VERSION "HIPBNNNYNNNNNNNNNNNNNNNNNNNNNNNNNNNNNNNNNN/4/%%%/4/'%**4NNN///"

NS_ :

BS_:

BU_: Vector__XXX xx TXU TSG SSG SMG RIP LWS Last INSTR GIB EKP EKAT EHC EGS EDCK DSC DME DIP DDE CRT CNG BFC BeCM ASP ASG ASC AIR_SUS ACC

BO_ 1584 RIP1: 8 RIP

BO_ 1583 TSG1: 8 TSG
 SG_ Vorzeichen : 7|1@1+ (1,0) [0|0] ""  DME
 SG_ T_UMG : 0|7@1+ (1,0) [0|0] "°C"  DME

BO_ 1567 INSTR6: 8 INSTR

BO_ 1562 INSTR5: 8 INSTR
 SG_ V_ODO_U m0 : 62|2@1+ (1,0) [0|0] ""  RIP
 SG_ V_COMP_U m1 : 61|1@1+ (1,0) [0|0] ""  RIP
 SG_ V_TEMP_U m1 : 60|1@1+ (1,0) [0|0] ""  RIP
 SG_ V_COMP_M m1 : 56|4@1+ (1,0) [0|0] ""  RIP
 SG_ V_TRIP1 m0 : 48|14@1+ (0.1,0) [0|6553.3] ""  RIP
 SG_ V_SIA m0 : 46|2@1+ (1,0) [0|0] ""  RIP
 SG_ V_ODO m0 : 24|20@1+ (1,0) [0|999999] ""  RIP
 SG_ V_COMP m1 : 24|16@1+ (1,0) [0|0] ""  RIP
 SG_ V_ID M : 22|2@1+ (1,0) [0|0] ""  RIP
 SG_ V_LED : 20|2@1+ (1,0) [0|0] ""  RIP
 SG_ V_WL : 8|12@1+ (1,0) [0|0] ""  RIP
 SG_ V_GPOS : 4|4@1+ (1,0) [0|0] ""  RIP
 SG_ V_GEAR : 0|4@1+ (1,0) [0|0] ""  RIP

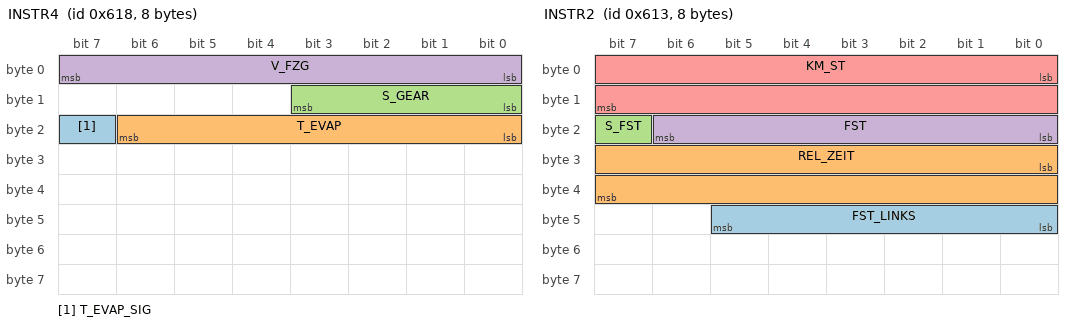
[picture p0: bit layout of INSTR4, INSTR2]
BO_ 1560 INSTR4: 8 INSTR
 SG_ T_EVAP_SIG : 23|1@1+ (1,0) [0|1] ""  DME,DDE
 SG_ T_EVAP : 16|7@1+ (1,0) [0|127] ""  DME,DDE
 SG_ S_GEAR : 8|4@1+ (1,0) [0|15] ""  ASC
 SG_ V_FZG : 0|8@1+ (1,0) [0|255] "km/h"  EGS,DME

BO_ 1557 INSTR3: 8 INSTR
 SG_ KEY_INFO : 56|3@1+ (1,0) [0|0] ""  DME
 SG_ V_ANZ : 46|10@1+ (0.5,0) [0|511] "km/h"  ACC
 SG_ F_K_OBD : 45|1@1+ (1,0) [0|1] ""  DME
 SG_ A_EKP_CRASH : 43|2@1+ (1,0) [0|3] ""  DDE,DME
 SG_ BLINKER : 41|2@1+ (1,0) [0|3] ""  ACC,DME
 SG_ F_K_ACC : 40|1@1+ (1,0) [0|1] ""  ACC,DME
 SG_ S_REGIME : 37|3@1+ (1,0) [0|7] ""  AIR_SUS,DME,EGS
 SG_ S_SUSP : 34|2@1+ (1,0) [0|3] ""  ASP,DME
 SG_ S_HBR : 33|1@1+ (1,0) [0|1] ""  ACC,ASC,ASP,DME,DSC
 SG_ S_DOOR : 32|1@1+ (1,0) [0|1] ""  ASP,DME
 SG_ T_UMG_SIGN : 31|1@1+ (1,0) [0|1] ""  DDE,DME
 SG_ T_UMG : 24|7@1+ (1,0) [0|127] "°C"  DME
 SG_ LB_NLL : 22|1@1+ (1,0) [0|0] ""  DDE,DME
 SG_ LB_USOLL : 16|6@1+ (0.1,0) [10.6|16.9] "V"  DDE,DME
 SG_ N_EL : 12|4@1+ (1,0) [0|15] ""  DDE,DME
 SG_ S_MH : 11|1@1+ (1,0) [0|0] ""  DME
 SG_ S_TNS : 10|1@1+ (1,0) [0|1] ""  DME,EDCK
 SG_ S_ANH : 9|1@1+ (1,0) [0|1] ""  DDE,DME
 SG_ S_HZL : 8|1@1+ (1,0) [0|1] ""  DDE,DME
 SG_ S_AC : 7|1@1+ (1,0) [0|1] ""  DDE,DME
 SG_ S_KO : 6|1@1+ (1,0) [0|1] ""  DDE,DME
 SG_ S_NTKW : 5|1@1+ (1,0) [0|1] ""  DME
 SG_ LM_KK : 0|5@1+ (1,0) [0|31] "Nm"  DDE,DME

BO_ 1555 INSTR2: 8 INSTR
 SG_ FST_LINKS : 40|6@1+ (1,0) [0|62] "Ltr."  DME
 SG_ REL_ZEIT : 24|16@1+ (1,0) [0|65535] "Min"  DSC,DME,ACC
 SG_ S_FST : 23|1@1+ (1,0) [0|0] ""  DME
 SG_ FST : 16|7@1+ (1,0) [0|126] "Ltr."  DME
 SG_ KM_ST : 0|16@1+ (10,0) [0|655340] "km"  EGS,DME

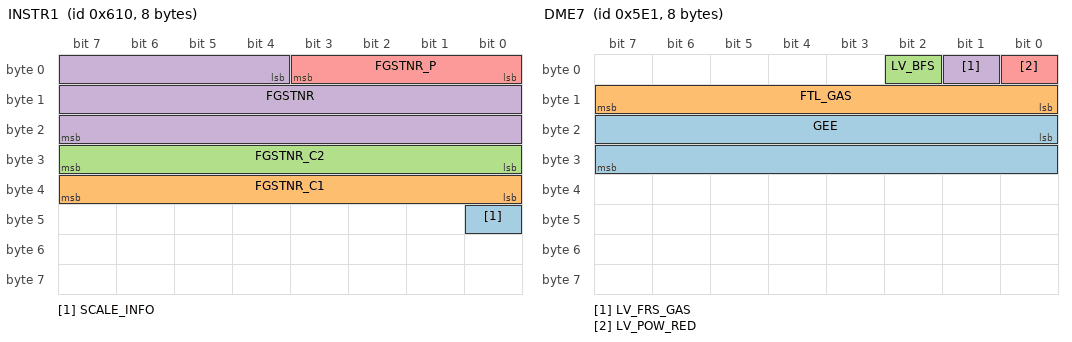
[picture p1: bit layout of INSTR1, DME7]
BO_ 1552 INSTR1: 8 INSTR
 SG_ SCALE_INFO : 40|1@1+ (1,0) [0|1] "" Vector__XXX
 SG_ FGSTNR_C1 : 32|8@1+ (1,0) [0|255] ""  LWS
 SG_ FGSTNR_C2 : 24|8@1+ (1,0) [0|255] ""  LWS
 SG_ FGSTNR : 4|20@1+ (1,0) [0|629145] ""  LWS
 SG_ FGSTNR_P : 0|4@1+ (1,0) [0|15] ""  LWS

BO_ 1505 DME7: 8 DME
 SG_ GEE : 16|16@1+ (0.003,0) [0|200] ""  INSTR
 SG_ FTL_GAS : 8|8@1+ (0.392,0) [0|99.96] "%"  INSTR
 SG_ LV_BFS : 2|1@1+ (1,0) [0|1] ""  INSTR
 SG_ LV_FRS_GAS : 1|1@1+ (1,0) [0|1] ""  INSTR
 SG_ LV_POW_RED : 0|1@1+ (1,0) [0|1] ""  INSTR

BO_ 1503 EDCK1: 8 EDCK
 SG_ EDCK_STA2 : 32|32@1+ (1,0) [0|4294970000] ""  xx
 SG_ EDCK_STA1 : 0|32@1+ (1,0) [0|4294970000] ""  xx

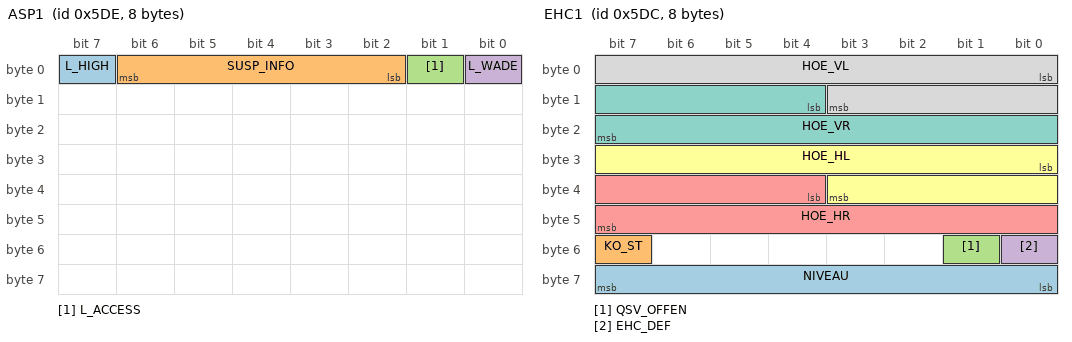
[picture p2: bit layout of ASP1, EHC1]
BO_ 1502 ASP1: 8 ASP
 SG_ L_HIGH : 7|1@1+ (1,0) [0|1] ""  BeCM
 SG_ SUSP_INFO : 2|5@1+ (1,0) [0|31] ""  BeCM
 SG_ L_ACCESS : 1|1@1+ (1,0) [0|1] ""  BeCM
 SG_ L_WADE : 0|1@1+ (1,0) [0|1] ""  BeCM

BO_ 1500 EHC1: 8 EHC
 SG_ NIVEAU : 56|8@1+ (1,0) [0|0] ""  DSC,EDCK
 SG_ KO_ST : 55|1@1+ (1,0) [0|1] ""  DME,DSC,EDCK
 SG_ QSV_OFFEN : 49|1@1+ (1,0) [0|0] ""  DSC,EDCK
 SG_ EHC_DEF : 48|1@1+ (1,0) [0|0] ""  DSC,EDCK
 SG_ HOE_HR : 36|12@1+ (1,-127) [0|127] "mm"  DSC,EDCK
 SG_ HOE_HL : 24|12@1+ (1,-127) [0|127] "mm"  DSC,EDCK
 SG_ HOE_VR : 12|12@1+ (0.25,-2048) [-511.75|511.5] "mm"  DSC,EDCK
 SG_ HOE_VL : 0|12@1+ (0.25,-2048) [-511.75|511.5] "mm"  DSC,EDCK

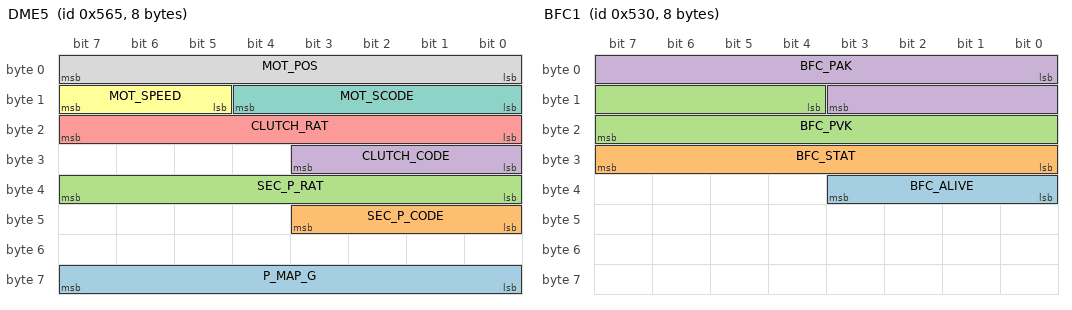
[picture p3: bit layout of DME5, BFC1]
BO_ 1381 DME5: 8 DME
 SG_ P_MAP_G : 56|8@1+ (1,-100) [-100|154] "Kpa"  xx
 SG_ SEC_P_CODE : 40|4@1+ (1,0) [0|0] ""  xx
 SG_ SEC_P_RAT : 32|8@1+ (0.19531,0) [0|49.804] ""  xx
 SG_ CLUTCH_CODE : 24|4@1+ (1,0) [0|0] ""  xx
 SG_ CLUTCH_RAT : 16|8@1+ (0.19531,0) [0|49.804] ""  xx
 SG_ MOT_SPEED : 13|3@1+ (1,0) [0|0] ""  xx
 SG_ MOT_SCODE : 8|5@1+ (1,0) [0|0] ""  xx
 SG_ MOT_POS : 0|8@1+ (1,0) [0|0] ""  xx

BO_ 1365 QYST1: 8 DME
 SG_ V_FZG_DME : 0|8@1+ (1,0) [0|254] "Km/h"  EGS

BO_ 1349 DME_DDE4: 8 DME
 SG_ L_P_OIL : 63|1@1+ (1,0) [0|0] ""  INSTR
 SG_ S_DDS : 56|1@1+ (1,0) [0|0] ""  DSC
 SG_ BEDARF_EKP : 48|8@1+ (1,0) [0|254] "ltr/h"  EKP
 SG_ S_KL30H : 47|1@1+ (1,0) [0|0] ""  INSTR
 SG_ I_DMESYS : 43|4@1+ (3,0) [0|45] "A"  INSTR
 SG_ GEN_LAST : 42|1@1+ (1,0) [0|1] ""  INSTR
 SG_ GEN_HTAR : 41|1@1+ (1,0) [0|1] ""  INSTR
 SG_ GEN_DEF : 40|1@1+ (1,0) [0|1] ""  INSTR
 SG_ M_OEL_TEMP : 32|8@1+ (1,-48) [-48|206] "°C"  INSTR
 SG_ SCHALT : 31|1@1+ (1,0) [0|0] ""  INSTR
 SG_ TMOT_KALT : 28|3@1+ (1,0) [0|7] ""  INSTR
 SG_ TMOT_STA : 27|1@1+ (1,0) [0|1] ""  INSTR
 SG_ MOL_SF : 26|1@1+ (1,0) [0|1] ""  INSTR
 SG_ MOL_VL : 25|1@1+ (1,0) [0|1] ""  INSTR
 SG_ MOL_VB : 24|1@1+ (1,0) [0|1] ""  INSTR
 SG_ VERBRAUCH : 8|16@1+ (1,0) [0|65535] "µLiter"  INSTR
 SG_ BATT_ANZ : 7|1@1+ (1,0) [0|1] ""  EKAT
 SG_ S_TDL : 6|1@1+ (1,0) [0|1] ""  INSTR
 SG_ L_BCF : 5|1@1+ (1,0) [0|1] ""  DIP
 SG_ L_DIAG : 4|1@1+ (1,0) [0|1] ""  INSTR
 SG_ L_FGR : 3|1@1+ (1,0) [0|1] ""  ACC,INSTR
 SG_ S_SHL : 2|1@1+ (1,0) [0|0] ""  INSTR
 SG_ L_MIL : 1|1@1+ (1,0) [0|1] ""  INSTR
 SG_ L_HEIZ : 0|1@1+ (1,0) [0|1] ""  DDE,INSTR

BO_ 1328 BFC1: 8 BFC
 SG_ BFC_ALIVE : 32|4@1+ (1,0) [0|0] ""  DSC
 SG_ BFC_STAT : 24|8@1+ (1,0) [0|0] ""  DSC
 SG_ BFC_PVK : 12|12@1+ (1,0) [0|0] ""  DSC
 SG_ BFC_PAK : 0|12@1+ (1,0) [0|0] ""  DSC

BO_ 1324 ACC1: 8 ACC
 SG_ ACC_GONG : 52|2@1+ (1,0) [0|3] ""  INSTR
 SG_ DIST_ANZ : 50|2@1+ (1,0) [0|3] ""  INSTR,DME
 SG_ SHIFTREQ : 49|1@1+ (1,0) [0|1] ""  INSTR,DME
 SG_ SEN_DTY : 48|1@1+ (1,0) [0|1] ""  INSTR,DME
 SG_ TAKEOVER : 47|1@1+ (1,0) [0|1] ""  DME
 SG_ OBJVALID : 46|1@1+ (1,0) [0|1] ""  INSTR,DME
 SG_ VSET : 40|6@1+ (5,0) [0|250] "kmph/mph"  INSTR,DME
 SG_ BRE_ACC : 32|8@1+ (0.390625,0) [0|255] "%"  EGS,DME,DDE,ASC
 SG_ MD_IND_ACC : 24|8@1+ (0.390625,0) [0|99.6094] "%"  EGS,DME,DDE,ASC
 SG_ VOBJECT m0 : 16|8@1+ (5,0) [0|250] "kmph/mph"  INSTR
 SG_ VISI_WARN m2 : 16|8@1+ (1,0) [0|255] "" Vector__XXX
 SG_ VISI_VAL m3 : 16|8@1+ (1,0) [0|255] "" Vector__XXX
 SG_ DIST_WARN m4 : 16|8@1+ (1,0) [0|255] "" Vector__XXX
 SG_ DIST_VAL m5 : 16|8@1+ (1,0) [0|255] "" Vector__XXX
 SG_ VSET2LOW m6 : 16|8@1+ (1,0) [0|255] "" Vector__XXX
 SG_ ACC_ALIVE : 12|4@1+ (1,0) [0|15] ""  DME,DDE,ASC
 SG_ ACC_MUL_CODE M : 8|4@1+ (1,0) [0|3] ""  xx
 SG_ B_MD_B_BRE : 6|2@1+ (1,0) [0|0] ""  DME,DDE,ASC
 SG_ ACC_STAT : 2|3@1+ (1,0) [0|7] ""  INSTR,EGS,DME,ASC
 SG_ ACC_DEF : 1|1@1+ (1,0) [0|1] ""  INSTR,EGS,DME,ASC
 SG_ ACC_VSA : 0|1@1+ (1,0) [0|1] ""  DME

BO_ 1315 EKAT1: 8 EKAT
 SG_ U_SBATT_LS1 m0 : 56|8@1+ (0.1,0) [0|25.5] "V"  DME
 SG_ U_SBATT_LS2 m1 : 56|8@1+ (0.1,0) [0|25.5] "V"  DME
 SG_ I_LS1 m0 : 48|8@1+ (1,0) [0|255] "A"  DME
 SG_ I_LS2 m1 : 48|8@1+ (1,0) [0|255] "A"  DME
 SG_ T_LS1 m0 : 41|7@1+ (2,-40) [0|214] "°C"  DME
 SG_ T_LS2 m1 : 41|7@1+ (2,-40) [0|214] "°C"  DME
 SG_ LS1_2 M : 40|1@1+ (1,0) [0|0] ""  DME
 SG_ T_BATT : 32|8@1+ (1,-40) [0|215] "°C"  DME
 SG_ KONV_BIT : 31|1@1+ (1,0) [0|1] ""  DME
 SG_ KAT_STAT2 : 16|8@1+ (1,0) [0|16777200] ""  DME
 SG_ KAT_STAT1 : 8|8@1+ (1,0) [0|16777200] ""  DME
 SG_ KAT_STAT0 : 0|8@1+ (1,0) [0|16777200] ""  DME

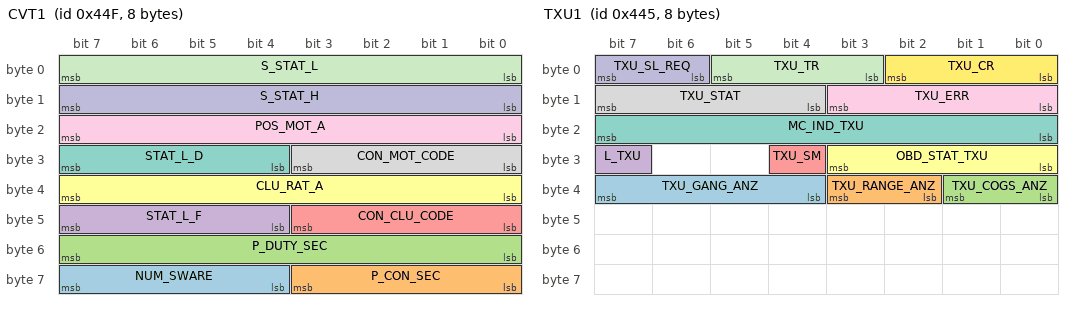
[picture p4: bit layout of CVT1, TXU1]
BO_ 1103 CVT1: 8 GIB
 SG_ NUM_SWARE : 60|4@1+ (1,0) [0|0] ""  xx
 SG_ P_CON_SEC : 56|4@1+ (1,0) [0|0] ""  xx
 SG_ P_DUTY_SEC : 48|8@1+ (0.19531,0) [0|49.804] ""  xx
 SG_ STAT_L_F : 44|4@1+ (1,0) [0|0] ""  xx
 SG_ CON_CLU_CODE : 40|4@1+ (1,0) [0|0] ""  xx
 SG_ CLU_RAT_A : 32|8@1+ (0.19531,0) [0|49.804] ""  xx
 SG_ STAT_L_D : 28|4@1+ (1,0) [0|0] ""  xx
 SG_ CON_MOT_CODE : 24|4@1+ (1,0) [0|0] ""  xx
 SG_ POS_MOT_A : 16|8@1+ (1,0) [0|0] ""  xx
 SG_ S_STAT_H : 8|8@1+ (1,0) [0|0] ""  xx
 SG_ S_STAT_L : 0|8@1+ (1,0) [0|0] ""  xx

BO_ 1097 CNG_DME1: 8 CNG
 SG_ VLS_GAS_2_PREV_DIAG : 56|8@1+ (0.005,0) [0|1.27] "Volt"  DME
 SG_ VLS_GAS_1_PREV_DIAG : 48|8@1+ (0.005,0) [0|1.27] "Volt"  DDE
 SG_ RAM_OUT : 40|8@1+ (1,0) [0|0] ""  CNG
 SG_ V_Q_GAS m2 : 32|8@1+ (0.0195,0) [0|4.9805] "Volt"  CNG
 SG_ V_TGAS_PCD m1 : 32|8@1+ (0.0195,0) [0|4.9805] "Volt"  CNG
 SG_ V_TGAS_H m3 : 32|8@1+ (0.0195,0) [0|4.9805] "Volt"  CNG
 SG_ V_TGAS_L m0 : 32|8@1+ (0.0195,0) [0|4.9805] "Volt"  CNG
 SG_ MUX_GAS M : 30|2@1+ (1,0) [0|0] ""  CNG
 SG_ SW_DET : 26|4@1+ (1,0) [0|0] ""  CNG
 SG_ V_PGAS_H : 16|10@1+ (0.0049,0) [0|4.9951] "Volt"  DME
 SG_ V_PGAS_L : 6|10@1+ (0.0049,0) [0|5.0078] "Volt"  DME
 SG_ LV_GIG_2 : 4|1@1+ (1,0) [0|0] ""  DME
 SG_ LV_DIG_1 : 3|1@1+ (1,0) [0|0] ""  DME
 SG_ LV_SWI_PGAS : 2|1@1+ (1,0) [0|0] ""  DME
 SG_ LV_CRASH : 1|1@1+ (1,0) [0|0] ""  DME
 SG_ LV_BFS : 0|1@1+ (1,0) [0|0] ""  CNG

BO_ 1095 DME_CNG1: 8 DME
 SG_ RAM_IN : 32|16@1+ (1,0) [0|0] ""  CNG
 SG_ T_PEAK_IV_GAS_TI : 24|8@1+ (0.08,0) [0|20.4] "ms"  CNG
 SG_ T_PEAK_EXPV : 16|8@1+ (0.08,0) [0|20.4] "ms"  CNG
 SG_ LV_OUT_4 : 15|1@1+ (1,0) [0|0] ""  CNG
 SG_ LV_HWP : 14|1@1+ (1,0) [0|0] ""  CNG
 SG_ LV_FUEL_ENA : 13|1@1+ (1,0) [0|0] ""  CNG
 SG_ LV_GAS_ENA : 12|1@1+ (1,0) [0|0] ""  CNG
 SG_ LV_LS_GAS_2_DIAG : 11|1@1+ (1,0) [0|0] ""  CNG
 SG_ LV_LS_GAS_1_DIAG : 10|1@1+ (1,0) [0|0] ""  CNG
 SG_ LV_OUT_2 : 9|1@1+ (1,0) [0|0] ""  CNG
 SG_ LV_OUT_1 : 8|1@1+ (1,0) [0|0] ""  CNG
 SG_ LV_HEAT_PCD : 7|1@1+ (1,0) [0|0] ""  CNG
 SG_ LV_SOV_GAS_PCD : 6|1@1+ (1,0) [0|0] ""  CNG
 SG_ LV_SOV_GAS_H_2 : 5|1@1+ (1,0) [0|0] ""  CNG
 SG_ LV_SOV_GAS_H_1 : 4|1@1+ (1,0) [0|0] ""  CNG
 SG_ LV_PEAK_IV_GAS_TI : 3|1@1+ (1,0) [0|0] ""  CNG
 SG_ LV_EXPV : 2|1@1+ (1,0) [0|0] ""  CNG
 SG_ LSHPWM_GAS_2 : 1|1@1+ (1,0) [0|0] ""  CNG
 SG_ LSHPWM_GAS_1 : 0|1@1+ (1,0) [0|0] ""  CNG

BO_ 1093 TXU1: 8 TXU
 SG_ TXU_GANG_ANZ : 36|4@1+ (1,0) [0|0] "" Vector__XXX
 SG_ TXU_RANGE_ANZ : 34|2@1+ (1,0) [0|0] "" Vector__XXX
 SG_ TXU_COGS_ANZ : 32|2@1+ (1,0) [0|0] "" Vector__XXX
 SG_ L_TXU : 31|1@1+ (1,0) [0|0] "" Vector__XXX
 SG_ TXU_SM : 28|1@1+ (1,0) [0|0] "" Vector__XXX
 SG_ OBD_STAT_TXU : 24|4@1+ (1,0) [0|0] "" Vector__XXX
 SG_ MC_IND_TXU : 16|8@1+ (0.390625,0) [0|99.6094] "%"  DME,DDE
 SG_ TXU_STAT : 12|4@1+ (1,0) [0|15] ""  BeCM
 SG_ TXU_ERR : 8|4@1+ (1,0) [0|15] ""  BeCM
 SG_ TXU_SL_REQ : 6|2@1+ (1,0) [0|0] "" Vector__XXX
 SG_ TXU_TR : 3|3@1+ (1,0) [0|7] ""  BeCM
 SG_ TXU_CR : 0|3@1+ (1,0) [0|7] ""  BeCM

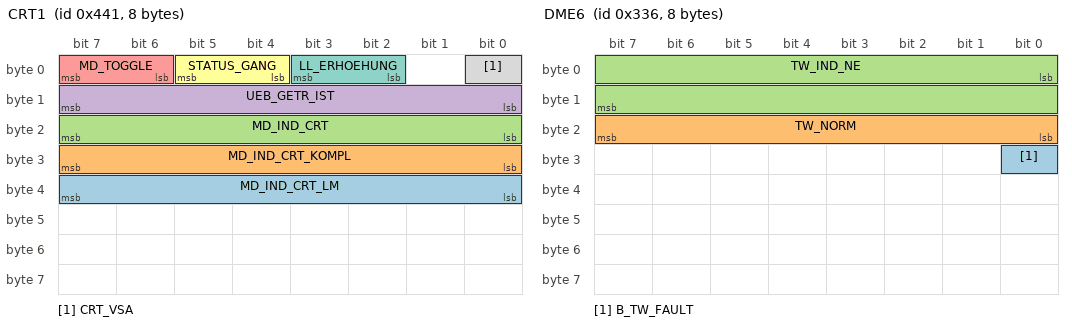
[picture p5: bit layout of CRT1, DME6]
BO_ 1089 CRT1: 8 CRT
 SG_ MD_IND_CRT_LM : 32|8@1+ (0.390625,0) [0|99.6094] "%"  DME
 SG_ MD_IND_CRT_KOMPL : 24|8@1+ (1,0) [0|0] ""  DME
 SG_ MD_IND_CRT : 16|8@1+ (0.390625,0) [0|99.6094] "%"  DME
 SG_ UEB_GETR_IST : 8|8@1+ (0.05,0) [0|12.7] ""  DME,DSC
 SG_ MD_TOGGLE : 6|2@1+ (1,0) [0|0] ""  DME
 SG_ STATUS_GANG : 4|2@1+ (1,0) [0|0] ""  DME
 SG_ LL_ERHOEHUNG : 2|2@1+ (1,0) [0|0] ""  DME
 SG_ CRT_VSA : 0|1@1+ (1,0) [0|0] ""  DME

BO_ 1087 EGS_SMG1: 8 EGS
 SG_ MD_GETRIEBE m0 : 56|8@1+ (0.390625,0) [0|99.6094] "%"  DME,DDE
 SG_ STR_VERST : 46|10@1+ (0.125,0) [0|127.75] "1/m"  DME,ACC
 SG_ S_GOT : 44|1@1+ (1,0) [0|1] ""  DME
 SG_ S_EGW : 43|1@1+ (1,0) [0|1] ""  DME
 SG_ GS_TYP M : 42|1@1+ (1,0) [0|3] ""  DME
 SG_ L_GS : 40|2@1+ (1,0) [0|3] ""  INSTR,DME,ACC
 SG_ N_ABTR : 32|8@1+ (1,0) [0|254] "1/min"  DME
 SG_ MD_IND_GS : 24|8@1+ (0.390625,0) [0|99.6094] "%"  DME,DDE
 SG_ PRG_INF_ANZ : 21|3@1+ (1,0) [0|7] ""  INSTR,DME
 SG_ SMG_WHL_ANZ : 16|2@1+ (1,0) [0|3] ""  INSTR
 SG_ OBD_STAT_GS : 12|4@1+ (1,0) [0|15] ""  DME
 SG_ GANG_WHL_ANZ : 8|4@1+ (1,0) [0|15] ""  INSTR,DME
 SG_ S_WK : 6|2@1+ (1,0) [0|3] ""  DME,DDE
 SG_ S_GTS : 5|1@1+ (1,0) [0|1] ""  DME
 SG_ OBD_F : 4|1@1+ (1,0) [0|1] ""  DME
 SG_ S_SCHALT : 3|1@1+ (1,0) [0|0] ""  DME,ASC
 SG_ GANG_INF : 0|3@1+ (1,0) [0|7] ""  DME,ASC

BO_ 1085 SSG1: 8 SSG

BO_ 824 DDE5: 0 DDE

BO_ 822 DME6: 8 DME
 SG_ B_TW_FAULT : 24|1@1+ (1,0) [0|0] ""  ASC
 SG_ TW_NORM : 16|8@1+ (1,0) [0|0] ""  ASC
 SG_ TW_IND_NE : 0|16@1+ (1,0) [0|0] ""  ASC

BO_ 809 DME_DDE2: 8 DME
 SG_ W_FPDK_MOD : 56|8@1+ (0.390625,0) [0|99.2188] "%"  ASC
 SG_ S_SHIFTLOCK : 54|2@1+ (1,0) [0|3] ""  EGS
 SG_ B_FGR : 51|3@1+ (1,0) [0|7] ""  ACC,EGS
 SG_ S_KD : 50|1@1+ (1,0) [0|1] ""  EGS
 SG_ F_BS : 49|1@1+ (1,0) [0|1] ""  ACC,ASC,DSC,EGS
 SG_ S_BS : 48|1@1+ (1,0) [0|1] ""  ACC,ASC,DSC,EGS
 SG_ W_FPDK : 40|8@1+ (0.390625,0) [0|99.2188] "%"  ACC,ASC,EGS
 SG_ W_VP_FGR : 32|8@1+ (0.390625,0) [0|99.2188] "%"  EGS
 SG_ BED_FGR : 29|3@1+ (1,0) [0|7] ""  ACC
 SG_ S_ML : 28|1@1+ (1,0) [0|1] ""  xx
 SG_ S_WL : 27|1@1+ (1,0) [0|1] ""  EGS
 SG_ Q_ACC_DME : 26|1@1+ (1,0) [0|1] ""  ACC
 SG_ S_NIV_LL : 25|1@1+ (1,0) [0|1] ""  EGS
 SG_ S_KUP : 24|1@1+ (1,0) [0|0] ""  ACC
 SG_ P_LUFT : 16|8@1+ (2,598) [600|1106] "hPa"  EGS
 SG_ T_MOT : 8|8@1+ (0.75,-48) [-48|142.5] "°C"  ASC,EGS,INSTR
 SG_ MUL_COD M : 6|2@1+ (1,0) [0|0] ""  ACC,ASC,EDCK,EGS,EHC,EKAT,INSTR,LWS
 SG_ EG_INFO m1 : 0|6@1+ (1,0) [0|0] ""  ACC,ASC,EGS
 SG_ MD_NORM m3 : 0|6@1+ (16,0) [0|1008] "Nm"  ACC,ASC,EGS
 SG_ OBD_STEUER m2 : 0|6@1+ (1,0) [0|3] ""  EGS
 SG_ CAN_STAND m0 : 0|6@1+ (1,0) [0|3] ""  ACC,ASC,EDCK,EGS,EHC,EKAT,INSTR,LWS

BO_ 790 DME_DDE1: 8 DME
 SG_ MD_IND_LM : 56|8@1+ (0.390625,0) [0|99.6094] "%"  ACC,ASC,EGS
 SG_ L_TP_SW : 53|1@1+ (1,0) [0|0] ""  ASC
 SG_ TP_SW : 52|1@1+ (1,0) [0|1] ""  ASC
 SG_ S_EZA : 51|1@1+ (1,0) [0|1] ""  ASC,DSC
 SG_ S_KATH2 : 49|1@1+ (1,0) [0|1] ""  EKAT
 SG_ S_KATH1 : 48|1@1+ (1,0) [0|1] ""  EKAT
 SG_ MD_REIB : 40|8@1+ (0.390625,0) [0|99.6094] "%"  ACC,ASC,DSC,EGS
 SG_ MD_IND : 32|8@1+ (0.390625,0) [0|99.6094] "%"  ACC,ASC,EGS
 SG_ N_MOT : 16|16@1+ (0.15625,0) [0|10239.8] "U/min"  ACC,ASC,EGS,INSTR
 SG_ MD_IND_NE : 8|8@1+ (0.390625,0) [0|99.6094] "%"  ACC,ASC,EGS
 SG_ F_TL_MES : 7|1@1+ (1,0) [0|1] ""  ACC,ASC,EGS
 SG_ S_KOREL : 6|1@1+ (1,0) [0|1] "" Vector__XXX
 SG_ STAT_MD_E : 4|2@1+ (1,0) [0|3] ""  ACC,ASC,DSC,EGS
 SG_ S_ZAF : 3|1@1+ (1,0) [0|1] ""  EGS
 SG_ Q_ASC : 2|1@1+ (1,0) [0|1] ""  ASC,DSC
 SG_ F_N_MOT : 1|1@1+ (1,0) [0|1] ""  ACC,ASC,EGS,INSTR
 SG_ S_KL15 : 0|1@1+ (1,0) [0|1] ""  ACC,ASC,DME,EDCK,EGS,EHC,EKAT,INSTR,LWS

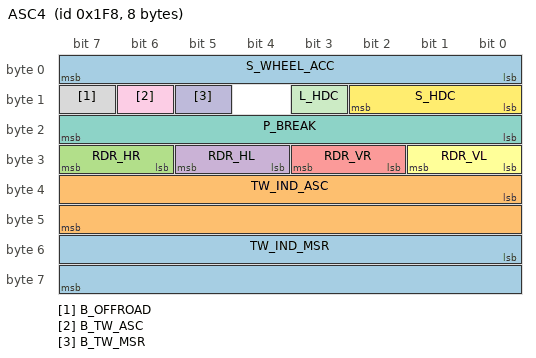
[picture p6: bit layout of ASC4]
BO_ 504 ASC4: 8 ASC
 SG_ TW_IND_MSR : 48|16@1+ (1,0) [0|0] "Nm"  DME
 SG_ TW_IND_ASC : 32|16@1+ (1,0) [0|0] "Nm"  DME
 SG_ RDR_HR : 30|2@1+ (1,0) [0|0] ""  EGS
 SG_ RDR_HL : 28|2@1+ (1,0) [0|0] ""  EGS
 SG_ RDR_VR : 26|2@1+ (1,0) [0|0] ""  EGS
 SG_ RDR_VL : 24|2@1+ (1,0) [0|0] ""  EGS
 SG_ P_BREAK : 16|8@1+ (1,0) [0|254] "bar"  EGS
 SG_ B_OFFROAD : 15|1@1+ (1,0) [0|0] ""  INSTR
 SG_ B_TW_ASC : 14|1@1+ (1,0) [0|0] ""  DME
 SG_ B_TW_MSR : 13|1@1+ (1,0) [0|0] ""  DME
 SG_ L_HDC : 11|1@1+ (1,0) [0|1] ""  INSTR
 SG_ S_HDC : 8|3@1+ (1,0) [0|7] ""  INSTR,EGS,DME
 SG_ S_WHEEL_ACC : 0|8@1+ (0.08,0) [0|2032] "g"  xx

BO_ 501 LWS1: 8 LWS
 SG_ LWS_BK_SIGN m2 : 63|1@1+ (1,0) [0|1] ""  DME
 SG_ LWS_PSIPKT_SIGN m1 : 63|1@1+ (1,0) [0|1] ""  DME
 SG_ LWS_AY_SIGN m0 : 63|1@1+ (1,0) [0|1] ""  DME
 SG_ LWS_BK m2 : 50|13@1+ (4E-05,0) [0|0.32764] "1/m"  DME
 SG_ LWS_AY m0 : 50|13@1+ (0.002,0) [0|16.382] "m/s/s"  DME
 SG_ LWS_PSIPKT m1 : 50|13@1+ (0.0002,0) [0|1.6382] "rad/s"  DME
 SG_ LWS_ANA m4 : 48|16@1+ (1,0) [0|65535] ""  DME
 SG_ LWS_CNT M : 44|4@1+ (1,0) [0|15] ""  ASC
 SG_ LWS_STAT : 40|4@1+ (1,0) [0|15] ""  EHC,EDCK,DSC,DME,ACC
 SG_ LWS_ID : 32|8@1+ (1,0) [0|255] ""  DSC,DME
 SG_ LWS_LRWPKT_SIGN : 31|1@1+ (1,0) [0|1] ""  EHC,EDCK,DSC,DME
 SG_ LWS_LRWPKT : 16|15@1+ (0.0439453,0) [0|1439.96] "Grad/s"  EHC,EDCK,DSC,DME
 SG_ LWS_LRW_SIGN : 15|1@1+ (1,0) [0|1] ""  EHC,EDCK,DSC,DME,ACC
 SG_ LWS_LRW : 0|15@1+ (0.0439453,0) [0|1439.96] "Grad"  EHC,EDCK,DSC,DME,ACC

BO_ 499 ASC3: 8 ASC
 SG_ S_FZGSTD : 59|1@1+ (1,0) [0|1] "" Vector__XXX
 SG_ L_DDS : 57|2@1+ (1,0) [0|0] ""  DME,INSTR
 SG_ DSC_DEF : 56|1@1+ (1,0) [0|0] ""  ACC,DME
 SG_ BAS_DATEN : 48|8@1+ (0.1,0) [0|25.5] "m/s*s"  ACC,DDE,DME,EGS
 SG_ AY_REF : 38|10@1+ (0.048,-24.576) [-24.576|24.48] "m/s*s"  ACC,ASG,DME,EGS,SMG
 SG_ BAS_CODE : 36|2@1+ (1,0) [0|0] "" Vector__XXX
 SG_ S_HBA : 35|1@1+ (1,0) [0|1] ""  ACC
 SG_ DSC_REG : 34|1@1+ (1,0) [0|1] ""  ACC,DME
 SG_ AX_REF : 24|10@1+ (0.03125,-15.9688) [-15.9688|15.9688] "m/s*s"  SMG
 SG_ BAS_STAT : 20|4@1+ (1,0) [0|15] ""  ACC,DME,EGS
 SG_ BAS_FBR : 18|2@1+ (1,0) [0|3] ""  ACC,DME,EGS
 SG_ Q_ACC_BAS : 17|1@1+ (1,0) [0|1] ""  ACC,DME
 SG_ BAS_DEF : 16|1@1+ (1,0) [0|1] ""  ACC
 SG_ FDR_PSIPKT_SIGN m0 : 15|1@1+ (1,0) [0|1] ""  ACC,DME,LWS
 SG_ FDR_ID m1 : 8|8@1+ (1,0) [0|255] ""  DME,LWS
 SG_ FDR_PSIPKT m0 : 5|9@1- (0.0021326,0) [0|1.08976] "rad/s"  ACC,DME,LWS
 SG_ FDR_PSIPKT_STATUS m0 : 1|2@1+ (1,0) [0|3] ""  ACC,DME,LWS
 SG_ FDR_COM M : 0|1@1+ (1,0) [0|0] ""  ACC,DME,LWS

BO_ 496 ASC2: 8 ASC
 SG_ TOL_RAD_X3 m2 : 61|3@1+ (1,0) [0|7] "" Vector__XXX
 SG_ VRD_RH_ASC : 48|13@1+ (0.0625,0) [2.75|512] "km/h"  EGS
 SG_ TOL_RAD_X2 m1 : 45|3@1+ (1,0) [0|7] "" Vector__XXX
 SG_ VRD_LH_ASC : 32|13@1+ (0.0625,0) [2.75|512] "km/h"  EGS
 SG_ TOL_RAD_X1 m0 : 29|3@1+ (1,0) [1|7] "" Vector__XXX
 SG_ VRD_RV_ASC : 16|13@1+ (0.0625,0) [2.75|512] "km/h"  EGS
 SG_ S_ABGL : 15|1@1+ (1,0) [0|1] "" Vector__XXX
 SG_ ASC2_COD M : 13|2@1+ (1,0) [0|0] "" Vector__XXX
 SG_ VRD_LV_ASC : 0|13@1+ (0.0625,0) [2.75|512] "km/h"  EGS

BO_ 339 ASC1: 8 ASC
 SG_ S_BFL : 63|1@1+ (1,0) [0|1] ""  INSTR
 SG_ S_RWF : 62|1@1+ (1,0) [0|1] ""  LWS
 SG_ L_BFC : 61|1@1+ (1,0) [0|0] ""  INSTR
 SG_ L_BKV : 60|1@1+ (1,0) [0|0] ""  INSTR
 SG_ L_FLUID : 59|1@1+ (1,0) [0|0] ""  INSTR
 SG_ S_ALR : 56|1@1+ (1,0) [0|17] ""  EGS
 SG_ MD_IND_ASC_LM : 48|8@1+ (0.390625,0) [0|99.6094] "%"  EGS,DME
 SG_ W_VDK : 40|8@1+ (0.390625,0) [0|99.2188] "%"  EGS,DME
 SG_ MD_IND_MSR : 32|8@1+ (0.390625,0) [0|99.6094] "%"  EGS,DME
 SG_ MD_IND_ASC : 24|8@1+ (0.390625,0) [0|99.6094] "%"  EGS,DME
 SG_ V1 : 11|13@1+ (0.0625,0) [2.75|512] "km/h"  EHC,DME,DDE
 SG_ F_V1 : 10|1@1+ (1,0) [0|1] ""  EHC,DME,DDE
 SG_ ASC_REG : 9|1@1+ (1,0) [0|1] ""  EGS,DME,ACC
 SG_ L_ASC : 8|1@1+ (1,0) [0|1] ""  ACC,DME,EGS,INSTR
 SG_ L_ABS : 7|1@1+ (1,0) [0|1] ""  DME,EGS
 SG_ L_EBV : 6|1@1+ (1,0) [0|1] ""  DME,INSTR
 SG_ L_BAS : 5|1@1+ (1,0) [0|1] ""  ACC,DME,INSTR
 SG_ S_BLS : 4|1@1+ (1,0) [0|1] ""  DME,DDE
 SG_ ASC_SBE : 3|1@1+ (1,0) [0|1] ""  DME,EGS
 SG_ ASC_PAS : 2|1@1+ (1,0) [0|1] ""  ACC,DME,EGS
 SG_ B_MSR : 1|1@1+ (1,0) [0|1] ""  ACC,DDE,DME
 SG_ B_ASC : 0|1@1+ (1,0) [0|1] ""  ACC,DDE,DME

EV_ U_S_Zeitraster_2: 0 [0|260] "" 260 376 DUMMY_NODE_VECTOR3  INSTR;

EV_ U_S_Zeitraster_1: 0 [0|260] "" 260 375 DUMMY_NODE_VECTOR3  INSTR;

EV_ U_S_TXU1_ZYKLUS_ZEIT: 0 [0|32767] "ms" 100 374 DUMMY_NODE_VECTOR3  xx,TXU;

EV_ U_S_TXU1_TOLERANZ_ZEIT: 0 [0|32767] "-" 10 373 DUMMY_NODE_VECTOR3  xx,TXU;

EV_ U_S_TXU1_SYNC_ZEIT: 0 [0|32767] "ms" 7 372 DUMMY_NODE_VECTOR3  xx,TXU;

EV_ U_S_TXU1_LATENZ_ZEIT: 0 [0|32767] "-" 10 371 DUMMY_NODE_VECTOR3  xx,TXU;

EV_ U_S_TXU_STARTUP_ZEIT: 0 [120|140] "ms" 120 370 DUMMY_NODE_VECTOR3  xx,TXU;

EV_ U_S_TXU_SENDEN_KL_15: 0 [0|1] "-" 0 369 DUMMY_NODE_VECTOR3  xx,TXU;

EV_ U_S_TXU_CAN_STAND: 0 [0|255] "-" 17 368 DUMMY_NODE_VECTOR3  xx,TXU;

EV_ U_S_LWS1_ZYKLUS_ZEIT: 0 [0|32767] "ms" 10 367 DUMMY_NODE_VECTOR3  LWS,xx;

EV_ U_S_LWS1_TOLERANZ_ZEIT: 0 [0|32767] "-" 3 366 DUMMY_NODE_VECTOR3  LWS,xx;

EV_ U_S_LWS1_SYNC_ZEIT: 0 [0|32767] "ms" 7 365 DUMMY_NODE_VECTOR3  LWS,xx;

EV_ U_S_LWS1_LATENZ_ZEIT: 0 [0|32767] "-" 7 364 DUMMY_NODE_VECTOR3  LWS,xx;

EV_ U_S_LWS_STARTUP_ZEIT: 0 [0|32767] "ms" 500 363 DUMMY_NODE_VECTOR3  LWS,xx;

EV_ U_S_LWS_SENDEN_KL_15: 0 [0|1] "-" 0 362 DUMMY_NODE_VECTOR3  LWS,xx;

EV_ U_S_LWS_CAN_STAND: 0 [0|255] "-" 17 361 DUMMY_NODE_VECTOR3  LWS,xx;

EV_ U_S_KOMBI_STARTUP_ZEIT: 0 [0|32767] "ms" 10 360 DUMMY_NODE_VECTOR3  INSTR,xx;

EV_ U_S_KOMBI_SENDEN_KL_15: 0 [0|1] "-" 1 359 DUMMY_NODE_VECTOR3  INSTR,xx;

EV_ U_S_KOMBI_CAN_STAND: 0 [0|255] "-" 17 358 DUMMY_NODE_VECTOR3  INSTR,xx;

EV_ U_S_KL_87_STARTUP_ZEIT: 0 [0|120] "ms" 50 357 DUMMY_NODE_VECTOR3  DDE,DME,xx;

EV_ U_S_KL_87_HALTEZEIT: 0 [8000|32767] "ms" 8000 356 DUMMY_NODE_VECTOR3  DDE,DME,xx;

EV_ U_S_KL_87_DREHZAHLSCHWELLE: 0 [0|32767] "Upm" 50 355 DUMMY_NODE_VECTOR3  DME,DDE,xx;

EV_ U_S_KL_87: 0 [0|1] "-" 0 354 DUMMY_NODE_VECTOR3  ACC,ASC,DME,EDCK,EGS,EHC,EKAT,INSTR,LWS,xx;

EV_ U_S_KL_15: 0 [0|1] "" 0 353 DUMMY_NODE_VECTOR3  INSTR,ACC,ASC,DME,EDCK,EGS,EHC,EKAT,INSTR,LWS;

EV_ U_S_INSTR4_ZYKLUS_ZEIT: 0 [0|32767] "ms" 200 352 DUMMY_NODE_VECTOR3  INSTR,xx;

EV_ U_S_INSTR4_TOLERANZ_ZEIT: 0 [0|32767] "-" 10 351 DUMMY_NODE_VECTOR3  INSTR,xx;

EV_ U_S_INSTR4_SYNC_ZEIT: 0 [0|32767] "ms" 0 350 DUMMY_NODE_VECTOR3  INSTR,xx;

EV_ U_S_INSTR4_LATENZ_ZEIT: 0 [0|32767] "-" 10 349 DUMMY_NODE_VECTOR3  INSTR,xx;

EV_ U_S_INSTR3_ZYKLUS_ZEIT: 0 [0|32767] "ms" 200 348 DUMMY_NODE_VECTOR3  xx,INSTR;

EV_ U_S_INSTR3_TOLERANZ_ZEIT: 0 [0|32767] "-" 100 347 DUMMY_NODE_VECTOR3  INSTR,xx;

EV_ U_S_INSTR3_SYNC_ZEIT: 0 [0|32767] "ms" 0 346 DUMMY_NODE_VECTOR3  INSTR,xx;

EV_ U_S_INSTR3_LATENZ_ZEIT: 0 [0|32767] "-" 100 345 DUMMY_NODE_VECTOR3  INSTR,xx;

EV_ U_S_INSTR2_ZYKLUS_ZEIT: 0 [0|32767] "ms" 200 344 DUMMY_NODE_VECTOR3  INSTR,xx;

EV_ U_S_INSTR2_TOLERANZ_ZEIT: 0 [0|32767] "-" 10000 343 DUMMY_NODE_VECTOR3  INSTR,xx;

EV_ U_S_INSTR2_SYNC_ZEIT: 0 [0|32767] "ms" 0 342 DUMMY_NODE_VECTOR3  INSTR,xx;

EV_ U_S_INSTR2_LATENZ_ZEIT: 0 [0|32767] "-" 50 341 DUMMY_NODE_VECTOR3  INSTR,xx;

EV_ U_S_INSTR1_ZYKLUS_ZEIT: 0 [0|32767] "ms" 100 340 DUMMY_NODE_VECTOR3  xx,INSTR;

EV_ U_S_INSTR1_TOLERANZ_ZEIT: 0 [0|32767] "-" 32767 339 DUMMY_NODE_VECTOR3  INSTR,xx;

EV_ U_S_INSTR1_SYNC_ZEIT: 0 [0|32767] "ms" 0 338 DUMMY_NODE_VECTOR3  INSTR,xx;

EV_ U_S_INSTR1_LATENZ_ZEIT: 0 [0|32767] "-" 10 337 DUMMY_NODE_VECTOR3  INSTR,xx;

EV_ U_S_EKAT1_ZYKLUS_ZEIT: 0 [0|100] "ms" 100 336 DUMMY_NODE_VECTOR3  xx,EKAT;

EV_ U_S_EKAT1_TOLERANZ_ZEIT: 0 [0|32767] "-" 10 335 DUMMY_NODE_VECTOR3  xx,EKAT;

EV_ U_S_EKAT1_SYNC_ZEIT: 0 [0|32767] "ms" 0 334 DUMMY_NODE_VECTOR3  xx,EKAT;

EV_ U_S_EKAT1_LATENZ_ZEIT: 0 [0|32767] "-" 50 333 DUMMY_NODE_VECTOR3  xx,EKAT;

EV_ U_S_EKAT_STARTUP_ZEIT: 0 [0|32767] "ms" 500 332 DUMMY_NODE_VECTOR3  xx,EKAT;

EV_ U_S_EKAT_SENDEN_KL_15: 0 [0|1] "-" 0 331 DUMMY_NODE_VECTOR3  xx,EKAT;

EV_ U_S_EKAT_CAN_STAND: 0 [0|255] "-" 17 330 DUMMY_NODE_VECTOR3  xx,EKAT;

EV_ U_S_EHC1_ZYKLUS_ZEIT: 0 [0|32767] "ms" 30 329 DUMMY_NODE_VECTOR3  EHC,xx;

EV_ U_S_EHC1_TOLERANZ_ZEIT: 0 [0|32767] "-" 50 328 DUMMY_NODE_VECTOR3  EHC,xx;

EV_ U_S_EHC1_SYNC_ZEIT: 0 [0|32767] "ms" 0 327 DUMMY_NODE_VECTOR3  EHC,xx;

EV_ U_S_EHC1_LATENZ_ZEIT: 0 [0|32767] "-" 50 326 DUMMY_NODE_VECTOR3  EHC,xx;

EV_ U_S_EHC_STARTUP_ZEIT: 0 [0|32767] "ms" 500 325 DUMMY_NODE_VECTOR3  EKAT,xx;

EV_ U_S_EHC_SENDEN_KL_15: 0 [0|1] "-" 0 324 DUMMY_NODE_VECTOR3  EKAT,xx;

EV_ U_S_EHC_CAN_STAND: 0 [0|255] "-" 17 323 DUMMY_NODE_VECTOR3  EHC,xx;

EV_ U_S_EGS1_ZYKLUS_ZEIT: 0 [0|32767] "ms" 100 322 DUMMY_NODE_VECTOR3  EGS,xx;

EV_ U_S_EGS1_TOLERANZ_ZEIT: 0 [0|32767] "-" 32767 321 DUMMY_NODE_VECTOR3  EGS,xx;

EV_ U_S_EGS1_SYNC_ZEIT: 0 [0|32767] "ms" 0 320 DUMMY_NODE_VECTOR3  EGS,xx;

EV_ U_S_EGS1_LATENZ_ZEIT: 0 [0|32767] "-" 50 319 DUMMY_NODE_VECTOR3  EGS,xx;

EV_ U_S_EGS_STARTUP_ZEIT: 0 [0|32767] "ms" 500 318 DUMMY_NODE_VECTOR3  EGS,xx;

EV_ U_S_EGS_SENDEN_KL_15: 0 [0|1] "-" 0 317 DUMMY_NODE_VECTOR3  EGS,xx;

EV_ U_S_EGS_CAN_STAND: 0 [0|255] "-" 17 316 DUMMY_NODE_VECTOR3  EGS,xx;

EV_ U_S_EDCK1_ZYKLUS_ZEIT: 0 [0|32767] "ms" 10 315 DUMMY_NODE_VECTOR3  EDCK,xx;

EV_ U_S_EDCK1_TOLERANZ_ZEIT: 0 [0|32767] "-" 50 314 DUMMY_NODE_VECTOR3  EDCK,xx;

EV_ U_S_EDCK1_SYNC_ZEIT: 0 [0|32767] "ms" 0 313 DUMMY_NODE_VECTOR3  EDCK,xx;

EV_ U_S_EDCK1_LATENZ_ZEIT: 0 [0|32767] "-" 50 312 DUMMY_NODE_VECTOR3  EDCK,xx;

EV_ U_S_EDCK_STARTUP_ZEIT: 0 [0|32767] "ms" 500 311 DUMMY_NODE_VECTOR3  EDCK,xx;

EV_ U_S_EDCK_SENDEN_KL_15: 0 [0|1] "-" 1 310 DUMMY_NODE_VECTOR3  EDCK,xx;

EV_ U_S_EDCK_CAN_STAND: 0 [0|255] "-" 17 309 DUMMY_NODE_VECTOR3  EDCK,xx;

EV_ U_S_DSC3_ZYKLUS_ZEIT: 0 [0|32767] "ms" 20 308 DUMMY_NODE_VECTOR3  DSC,xx;

EV_ U_S_DSC3_TOLERANZ_ZEIT: 0 [0|32767] "-" 10 307 DUMMY_NODE_VECTOR3  DSC,xx;

EV_ U_S_DSC3_SYNC_ZEIT: 0 [0|32767] "ms" 0 306 DUMMY_NODE_VECTOR3  DSC,xx;

EV_ U_S_DSC3_LATENZ_ZEIT: 0 [0|32767] "-" 50 305 DUMMY_NODE_VECTOR3  DSC,xx;

EV_ U_S_DSC2_ZYKLUS_ZEIT: 0 [0|32767] "ms" 20 304 DUMMY_NODE_VECTOR3  DSC,xx;

EV_ U_S_DSC2_TOLERANZ_ZEIT: 0 [0|32767] "-" 10 303 DUMMY_NODE_VECTOR3  DSC,xx;

EV_ U_S_DSC2_SYNC_ZEIT: 0 [0|32767] "ms" 0 302 DUMMY_NODE_VECTOR3  DSC,xx;

EV_ U_S_DSC2_LATENZ_ZEIT: 0 [0|32767] "-" 50 301 DUMMY_NODE_VECTOR3  DSC,xx;

EV_ U_S_DSC1_ZYKLUS_ZEIT: 0 [0|32767] "ms" 20 300 DUMMY_NODE_VECTOR3  DSC,xx;

EV_ U_S_DSC1_TOLERANZ_ZEIT: 0 [0|32767] "-" 10 299 DUMMY_NODE_VECTOR3  DSC,xx;

EV_ U_S_DSC1_SYNC_ZEIT: 0 [0|32767] "ms" 0 298 DUMMY_NODE_VECTOR3  DSC,xx;

EV_ U_S_DSC1_LATENZ_ZEIT: 0 [0|32767] "-" 50 297 DUMMY_NODE_VECTOR3  DSC,xx;

EV_ U_S_DSC_STARTUP_ZEIT: 0 [0|32767] "" 500 296 DUMMY_NODE_VECTOR3  DSC,xx;

EV_ U_S_DSC_SENDEN_KL_15: 0 [0|1] "" 0 295 DUMMY_NODE_VECTOR3  DSC,xx;

EV_ U_S_DSC_CAN_STAND: 0 [0|255] "-" 17 294 DUMMY_NODE_VECTOR3  DSC,xx;

EV_ U_S_DME4_ZYKLUS_ZEIT: 0 [0|32767] "ms" 10 293 DUMMY_NODE_VECTOR3  DME,xx;

EV_ U_S_DME4_TOLERANZ_ZEIT: 0 [0|32767] "-" 60 292 DUMMY_NODE_VECTOR3  DME,xx;

EV_ U_S_DME4_SYNC_ZEIT: 0 [0|32767] "ms" 0 291 DUMMY_NODE_VECTOR3  DME,xx;

EV_ U_S_DME4_LATENZ_ZEIT: 0 [0|32767] "-" 50 290 DUMMY_NODE_VECTOR3  DME,xx;

EV_ U_S_DME2_ZYKLUS_ZEIT: 0 [0|32767] "ms" 10 289 DUMMY_NODE_VECTOR3  DME,xx;

EV_ U_S_DME2_TOLERANZ_ZEIT: 0 [0|32767] "-" 60 288 DUMMY_NODE_VECTOR3  DME,xx;

EV_ U_S_DME2_SYNC_ZEIT: 0 [0|32767] "ms" 0 287 DUMMY_NODE_VECTOR3  DME,xx;

EV_ U_S_DME2_LATENZ_ZEIT: 0 [0|32767] "-" 50 286 DUMMY_NODE_VECTOR3  DME,xx;

EV_ U_S_DME1_ZYKLUS_ZEIT: 0 [0|32767] "ms" 10 285 DUMMY_NODE_VECTOR3  DME,xx;

EV_ U_S_DME1_TOLERANZ_ZEIT: 0 [0|32767] "-" 60 284 DUMMY_NODE_VECTOR3  DME,xx;

EV_ U_S_DME1_SYNC_ZEIT: 0 [0|32767] "ms" 0 283 DUMMY_NODE_VECTOR3  DME,xx;

EV_ U_S_DME1_LATENZ_ZEIT: 0 [0|32767] "-" 50 282 DUMMY_NODE_VECTOR3  DME,xx;

EV_ U_S_DME_STARTUP_ZEIT: 0 [0|32767] "ms" 120 281 DUMMY_NODE_VECTOR3  DME,xx;

EV_ U_S_DME_SENDEN_KL_15: 0 [0|1] "-" 0 280 DUMMY_NODE_VECTOR3  DME,xx;

EV_ U_S_DME_CAN_STAND: 0 [0|255] "-" 17 279 DUMMY_NODE_VECTOR3  DME,xx;

EV_ U_S_DDE4_ZYKLUS_ZEIT: 0 [0|32767] "ms" 20 278 DUMMY_NODE_VECTOR3  DDE,xx;

EV_ U_S_DDE4_TOLERANZ_ZEIT: 0 [0|32767] "-" 10 277 DUMMY_NODE_VECTOR3  DDE,xx;

EV_ U_S_DDE4_SYNC_ZEIT: 0 [0|32767] "ms" 0 276 DUMMY_NODE_VECTOR3  DDE,xx;

EV_ U_S_DDE4_LATENZ_ZEIT: 0 [0|32767] "-" 50 275 DUMMY_NODE_VECTOR3  DDE,xx;

EV_ U_S_DDE2_ZYKLUS_ZEIT: 0 [0|32767] "ms" 20 274 DUMMY_NODE_VECTOR3  DDE,xx;

EV_ U_S_DDE2_TOLERANZ_ZEIT: 0 [0|32767] "-" 10 273 DUMMY_NODE_VECTOR3  DDE,xx;

EV_ U_S_DDE2_SYNC_ZEIT: 0 [0|32767] "ms" 0 272 DUMMY_NODE_VECTOR3  DDE,xx;

EV_ U_S_DDE2_LATENZ_ZEIT: 0 [0|32767] "-" 50 271 DUMMY_NODE_VECTOR3  DDE,xx;

EV_ U_S_DDE1_ZYKLUS_ZEIT: 0 [0|32767] "ms" 20 270 DUMMY_NODE_VECTOR3  DDE,xx;

EV_ U_S_DDE1_TOLERANZ_ZEIT: 0 [0|32767] "-" 10 269 DUMMY_NODE_VECTOR3  DDE,xx;

EV_ U_S_DDE1_SYNC_ZEIT: 0 [0|32767] "ms" 0 268 DUMMY_NODE_VECTOR3  DDE,xx;

EV_ U_S_DDE1_LATENZ_ZEIT: 0 [0|32767] "-" 50 267 DUMMY_NODE_VECTOR3  DDE,xx;

EV_ U_S_DDE_STARTUP_ZEIT: 0 [0|32767] "ms" 120 266 DUMMY_NODE_VECTOR3  DDE,xx;

EV_ U_S_DDE_SENDEN_KL_15: 0 [0|1] "-" 0 265 DUMMY_NODE_VECTOR3  DDE,xx;

EV_ U_S_DDE_CAN_STAND: 0 [0|255] "-" 17 264 DUMMY_NODE_VECTOR3  DDE,xx;

EV_ U_S_ASP1_ZYKLUS_ZEIT: 0 [0|32767] "ms" 200 263 DUMMY_NODE_VECTOR3  xx,ASP;

EV_ U_S_ASP1_TOLERANZ_ZEIT: 0 [0|32767] "-" 32767 262 DUMMY_NODE_VECTOR3  xx,ASP;

EV_ U_S_ASP1_SYNC_ZEIT: 0 [0|32767] "ms" 0 261 DUMMY_NODE_VECTOR3  xx,ASP;

EV_ U_S_ASP1_LATENZ_ZEIT: 0 [0|32767] "-" 20 260 DUMMY_NODE_VECTOR3  xx,ASP;

EV_ U_S_ASP_STARTUP_ZEIT: 0 [120|140] "ms" 120 259 DUMMY_NODE_VECTOR3  xx,ASP;

EV_ U_S_ASP_SENDEN_KL_15: 0 [0|1] "-" 0 258 DUMMY_NODE_VECTOR3  xx,ASP;

EV_ U_S_ASP_CAN_STAND: 0 [0|255] "-" 17 257 DUMMY_NODE_VECTOR3  xx,ASP;

EV_ U_S_ASG1_ZYKLUS_ZEIT: 0 [0|32767] "ms" 10 256 DUMMY_NODE_VECTOR3  ASG,xx;

EV_ U_S_ASG1_TOLERANZ_ZEIT: 0 [0|32767] "-" 50 255 DUMMY_NODE_VECTOR3  ASG,xx;

EV_ U_S_ASG1_SYNC_ZEIT: 0 [0|32767] "ms" 0 254 DUMMY_NODE_VECTOR3  ASG,xx;

EV_ U_S_ASG1_LATENZ_ZEIT: 0 [0|32767] "-" 50 253 DUMMY_NODE_VECTOR3  ASG,xx;

EV_ U_S_ASG_STARTUP_ZEIT: 0 [0|32767] "ms" 500 252 DUMMY_NODE_VECTOR3  ASG,xx;

EV_ U_S_ASG_SENDEN_KL_15: 0 [0|1] "-" 0 251 DUMMY_NODE_VECTOR3  ASG,xx;

EV_ U_S_ASG_CAN_STAND: 0 [0|255] "-" 17 250 DUMMY_NODE_VECTOR3  ASG,xx;

EV_ U_S_ASC4_ZYKLUS_ZEIT: 0 [0|10000] "ms" 10 249 DUMMY_NODE_VECTOR3  xx,ASC;

EV_ U_S_ASC3_ZYKLUS_ZEIT: 0 [0|10000] "ms" 10 248 DUMMY_NODE_VECTOR3  xx,ASC;

EV_ U_S_ASC3_TOLERANZ_ZEIT: 0 [0|32767] "-" 10 247 DUMMY_NODE_VECTOR3  xx,ASC;

EV_ U_S_ASC3_SYNC_ZEIT: 0 [0|32767] "ms" 0 246 DUMMY_NODE_VECTOR3  xx,ASC;

EV_ U_S_ASC3_LATENZ_ZEIT: 0 [0|32767] "-" 50 245 DUMMY_NODE_VECTOR3  xx,ASC;

EV_ U_S_ASC2_ZYKLUS_ZEIT: 0 [0|32000] "ms" 10 244 DUMMY_NODE_VECTOR3  xx,ASC;

EV_ U_S_ASC2_TOLERANZ_ZEIT: 0 [0|32767] "-" 10 243 DUMMY_NODE_VECTOR3  ASC,xx;

EV_ U_S_ASC2_SYNC_ZEIT: 0 [0|32767] "ms" 0 242 DUMMY_NODE_VECTOR3  ASC,xx;

EV_ U_S_ASC2_LATENZ_ZEIT: 0 [0|32767] "-" 50 241 DUMMY_NODE_VECTOR3  ASC,xx;

EV_ U_S_ASC1_ZYKLUS_ZEIT: 0 [0|32000] "ms" 10 240 DUMMY_NODE_VECTOR3  ASC,xx;

EV_ U_S_ASC1_TOLERANZ_ZEIT: 0 [0|32767] "-" 10 239 DUMMY_NODE_VECTOR3  ASC,xx;

EV_ U_S_ASC1_SYNC_ZEIT: 0 [0|32767] "ms" 0 238 DUMMY_NODE_VECTOR3  ASC,xx;

EV_ U_S_ASC1_LATENZ_ZEIT: 0 [0|32767] "0.1ms" 50 237 DUMMY_NODE_VECTOR3  ASC,xx;

EV_ U_S_ASC_STARTUP_ZEIT: 0 [0|32767] "ms" 200 236 DUMMY_NODE_VECTOR3  xx,ASC;

EV_ U_S_ASC_SENDEN_KL_15: 0 [0|1] "-" 0 235 DUMMY_NODE_VECTOR3  ASC,xx;

EV_ U_S_ASC_CAN_STAND: 0 [0|255] "-" 17 234 DUMMY_NODE_VECTOR3  ASC,xx;

EV_ U_S_ACC3_TOLERANZ_ZEIT: 0 [0|50] "-" 50 233 DUMMY_NODE_VECTOR3  xx,ACC;

EV_ U_S_ACC1_ZYKLUS_ZEIT: 0 [0|32000] "ms" 20 232 DUMMY_NODE_VECTOR3  xx,ACC;

EV_ U_S_ACC1_TOLERANZ_ZEIT: 0 [0|32767] "-" 50 231 DUMMY_NODE_VECTOR3  ACC,xx;

EV_ U_S_ACC1_SYNC_ZEIT: 0 [0|32767] "ms" 0 230 DUMMY_NODE_VECTOR3  ACC,xx;

EV_ U_S_ACC1_LATENZ_ZEIT: 0 [0|32767] "-" 50 229 DUMMY_NODE_VECTOR3  ACC,xx;

EV_ U_S_ACC_STARTUP_ZEIT: 0 [0|32767] "ms" 50 228 DUMMY_NODE_VECTOR3  xx,ACC;

EV_ U_S_ACC_SENDEN_KL_15: 0 [0|1] "" 1 227 DUMMY_NODE_VECTOR3  ACC,xx;

EV_ U_S_ACC_CAN_STAND: 0 [0|255] "" 17 226 DUMMY_NODE_VECTOR3  ACC,xx;

EV_ U_H_Momenteneingriff_MSR_2: 1 [0|255] "" 0 225 DUMMY_NODE_VECTOR3  ASC;

EV_ U_H_Momenteneingriff_MSR_1: 1 [0|255] "" 0 224 DUMMY_NODE_VECTOR3  ASC;

EV_ U_H_Momenteneingriff_EGS: 1 [0|99.61] "" 0 223 DUMMY_NODE_VECTOR0 Vector__XXX;

EV_ U_H_Momenteneingriff_ASC_2: 1 [0|255] "" 0 222 DUMMY_NODE_VECTOR0 Vector__XXX;

EV_ U_H_Momenteneingriff_ASC_1: 1 [0|255] "" 0 221 DUMMY_NODE_VECTOR3  ASC;

EV_ U_H_Momenteingriff_ACC: 1 [-20|275] "" 0 220 DUMMY_NODE_VECTOR0  ACC,AIR_SUS,ASC,ASG,ASP,BeCM,DDE,DIP,DME,DSC,EDCK,EGS,EHC,EKAT,INSTR,Last,LWS,TXU,xx;

EV_ U_H_EKAT_Status_9: 0 [0|1] "" 0 219 DUMMY_NODE_VECTOR3  EKAT;

EV_ U_H_EKAT_Status_8: 0 [0|1] "" 0 218 DUMMY_NODE_VECTOR3  EKAT;

EV_ U_H_EKAT_Status_7: 0 [0|1] "" 0 217 DUMMY_NODE_VECTOR3  EKAT;

EV_ U_H_EKAT_Status_6: 0 [0|1] "" 0 216 DUMMY_NODE_VECTOR3  EKAT;

EV_ U_H_EKAT_Status_5: 0 [0|1] "" 0 215 DUMMY_NODE_VECTOR3  EKAT;

EV_ U_H_EKAT_Status_4: 0 [0|1] "" 0 214 DUMMY_NODE_VECTOR3  EKAT;

EV_ U_H_EKAT_Status_3: 0 [0|1] "" 0 213 DUMMY_NODE_VECTOR3  EKAT;

EV_ U_H_EKAT_Status_23: 0 [0|1] "" 0 212 DUMMY_NODE_VECTOR3  EKAT;

EV_ U_H_EKAT_Status_22: 0 [0|1] "" 0 211 DUMMY_NODE_VECTOR3  EKAT;

EV_ U_H_EKAT_Status_21: 0 [0|1] "" 0 210 DUMMY_NODE_VECTOR3  EKAT;

EV_ U_H_EKAT_Status_20: 0 [0|1] "" 0 209 DUMMY_NODE_VECTOR3  EKAT;

EV_ U_H_EKAT_Status_2: 0 [0|1] "" 0 208 DUMMY_NODE_VECTOR3  EKAT;

EV_ U_H_EKAT_Status_19: 0 [0|1] "" 0 207 DUMMY_NODE_VECTOR3  EKAT;

EV_ U_H_EKAT_Status_18: 0 [0|1] "" 0 206 DUMMY_NODE_VECTOR3  EKAT;

EV_ U_H_EKAT_Status_17: 0 [0|1] "" 0 205 DUMMY_NODE_VECTOR3  EKAT;

EV_ U_H_EKAT_Status_16: 0 [0|1] "" 0 204 DUMMY_NODE_VECTOR3  EKAT;

EV_ U_H_EKAT_Status_15: 0 [0|1] "" 0 203 DUMMY_NODE_VECTOR3  EKAT;

EV_ U_H_EKAT_Status_14: 0 [0|1] "" 0 202 DUMMY_NODE_VECTOR3  EKAT;

EV_ U_H_EKAT_Status_13: 0 [0|1] "" 0 201 DUMMY_NODE_VECTOR3  EKAT;

EV_ U_H_EKAT_Status_12: 0 [0|1] "" 0 200 DUMMY_NODE_VECTOR3  EKAT;

EV_ U_H_EKAT_Status_11: 0 [0|1] "" 0 199 DUMMY_NODE_VECTOR3  EKAT;

EV_ U_H_EKAT_Status_10: 0 [0|1] "" 0 198 DUMMY_NODE_VECTOR3  EKAT;

EV_ U_H_EKAT_Status_1: 0 [0|1] "" 0 197 DUMMY_NODE_VECTOR3  EKAT;

EV_ U_H_EKAT_Status_0: 0 [0|1] "" 0 196 DUMMY_NODE_VECTOR3  EKAT;

EV_ U_H_EKAT_Auswahl_3: 0 [0|500] "" 0 195 DUMMY_NODE_VECTOR3  EKAT;

EV_ U_H_EKAT_Auswahl_2: 0 [0|500] "" 0 194 DUMMY_NODE_VECTOR3  EKAT;

EV_ U_H_EKAT_Auswahl_1: 0 [0|500] "" 0 193 DUMMY_NODE_VECTOR3  EKAT;

EV_ U_H_Bremseingriff_ACC: 1 [-20|275] "" 0 192 DUMMY_NODE_VECTOR3  ACC,AIR_SUS,ASC,ASG,ASP,BeCM,DDE,DIP,DME,DSC,EDCK,EGS,EHC,EKAT,INSTR,Last,LWS,TXU,xx;

EV_ U_H_ASC3_Offset_Umrechnung: 1 [0|25.5] "" 0 191 DUMMY_NODE_VECTOR3  ASC;

EV_ U_H_ASC3_Normierungsfaktor: 1 [0|25.5] "" 0 190 DUMMY_NODE_VECTOR3  ASC;

EV_ U_H_ASC3_Init_Lenkwinkelsensor: 1 [0|255] "" 0 189 DUMMY_NODE_VECTOR3  ASC;

EV_ U_H_ASC3_Giergeschwindigkeit: 1 [0|62.44] "" 1.08976 188 DUMMY_NODE_VECTOR3  ASC;

EV_ U_H_ASC3_Giergeschw_Vorzeichen: 0 [0|1] "0" 0 187 DUMMY_NODE_VECTOR3  ASC;

EV_ U_H_ASC3_Giergeschw_Status: 0 [0|4] "0" 0 186 DUMMY_NODE_VECTOR3  ASC;

EV_ U_H_ASC3_Ansprechhysterese1: 1 [0|0] "" 0 185 DUMMY_NODE_VECTOR3  ASC;

EV_ U_H_ASC3_Ansprechhysterese: 1 [0|0] "" 0 184 DUMMY_NODE_VECTOR3  ASC;

EV_ U_H_ASC2_VZ_Radgeschw_VR: 0 [0|1] "" 0 183 DUMMY_NODE_VECTOR3  ASC;

EV_ U_H_ASC2_VZ_Radgeschw_VL: 0 [0|1] "" 0 182 DUMMY_NODE_VECTOR3  ASC;

EV_ U_H_ASC2_VZ_Radgeschw_HR: 0 [0|1] "" 0 181 DUMMY_NODE_VECTOR3  ASC;

EV_ U_H_ASC2_VZ_Radgeschw_HL: 0 [0|1] "" 0 180 DUMMY_NODE_VECTOR3  ASC;

EV_ U_H_ASC2_Radtoleranz_VR: 0 [0|496] "" 0 179 DUMMY_NODE_VECTOR3  ASC;

EV_ U_H_ASC2_Radtoleranz_VL: 0 [0|496] "" 0 178 DUMMY_NODE_VECTOR3  ASC;

EV_ U_H_ASC2_Radtoleranz_HR: 0 [0|496] "" 0 177 DUMMY_NODE_VECTOR3  ASC;

EV_ U_H_ASC2_Radgeschw_Gesp_VR: 0 [0|1] "" 0 176 DUMMY_NODE_VECTOR3  ASC;

EV_ U_H_ASC2_Radgeschw_Gesp_VL: 0 [0|1] "" 0 175 DUMMY_NODE_VECTOR3  ASC;

EV_ U_H_ASC2_Radgeschw_Gesp_HR: 0 [0|1] "" 0 174 DUMMY_NODE_VECTOR3  ASC;

EV_ U_H_ASC2_Radgeschw_Gesp_HL: 0 [0|1] "" 0 173 DUMMY_NODE_VECTOR3  ASC;

EV_ U_H_ASC2_Radabgleichwert_VR_3: 0 [0|7] "" 0 172 DUMMY_NODE_VECTOR3  ASC;

EV_ U_H_ASC2_Radabgleichwert_VR_2: 0 [0|7] "" 0 171 DUMMY_NODE_VECTOR3  ASC;

EV_ U_H_ASC2_Radabgleichwert_VR_1: 0 [0|7] "" 0 170 DUMMY_NODE_VECTOR3  ASC;

EV_ U_H_ASC2_Radabgleichwert_VL_3: 0 [0|7] "" 0 169 DUMMY_NODE_VECTOR3  ASC;

EV_ U_H_ASC2_Radabgleichwert_VL_2: 0 [0|7] "" 0 168 DUMMY_NODE_VECTOR3  ASC;

EV_ U_H_ASC2_Radabgleichwert_VL_1: 0 [0|7] "" 0 167 DUMMY_NODE_VECTOR3  ASC;

EV_ U_H_ASC2_Radabgleichwert_HR_3: 0 [0|7] "" 0 166 DUMMY_NODE_VECTOR3  ASC;

EV_ U_H_ASC2_Radabgleichwert_HR_2: 0 [0|7] "" 0 165 DUMMY_NODE_VECTOR3  ASC;

EV_ U_H_ASC2_Radabgleichwert_HR_1: 0 [0|7] "" 0 164 DUMMY_NODE_VECTOR3  ASC;

EV_ U_H_ASC2_Radabgleichwert_HL_3: 0 [0|7] "" 0 163 DUMMY_NODE_VECTOR3  ASC;

EV_ U_H_ASC2_Radabgleichwert_HL_2: 0 [0|7] "" 0 162 DUMMY_NODE_VECTOR3  ASC;

EV_ U_H_ASC2_Radabgleichwert_HL_1: 0 [0|7] "" 0 161 DUMMY_NODE_VECTOR3  ASC;

EV_ U_H_ASC2_Radabgleich_VR: 0 [0|1] "" 0 160 DUMMY_NODE_VECTOR3  ASC;

EV_ U_H_ASC2_Radabgleich_VL: 0 [0|1] "" 0 159 DUMMY_NODE_VECTOR3  ASC;

EV_ U_H_ASC2_Radabgleich_HR: 0 [0|1] "" 0 158 DUMMY_NODE_VECTOR3  ASC;

EV_ U_H_ASC2_Radabgleich_HL: 0 [0|1] "" 0 157 DUMMY_NODE_VECTOR3  ASC;

EV_ U_E_Zielgang: 0 [0|8] "" 0 156 DUMMY_NODE_VECTOR3  EGS;

EV_ U_E_Winkel_Vordrosselklappe: 1 [0|99.3] "" 0 155 DUMMY_NODE_VECTOR3  ASC;

EV_ U_E_Wandlerkupplung: 0 [0|4] "" 0 154 DUMMY_NODE_VECTOR3  EGS;

EV_ U_E_VSET2LOW: 0 [0|10000] "" 0 153 DUMMY_NODE_VECTOR3  DME;

EV_ U_E_VISI_WARN: 0 [0|1000] "" 0 152 DUMMY_NODE_VECTOR3  DME;

EV_ U_E_VISI_VAL: 0 [0|1000] "" 0 151 DUMMY_NODE_VECTOR3  DME;

EV_ U_E_Verhinderung_Schubabschalt: 0 [0|1] "" 0 150 DUMMY_NODE_VECTOR3  DME;

EV_ U_E_Verbrauch: 1 [0|100] "l/100km" 0 149 DUMMY_NODE_VECTOR3  DME,DME;

EV_ U_E_V1: 1 [0|511.938] "" 0 148 DUMMY_NODE_VECTOR3  ASC;

EV_ U_E_Tempomat: 0 [0|1] "" 0 147 DUMMY_NODE_VECTOR3  DME,DME;

EV_ U_E_T_MOT: 1 [-48|142] "Grad" 20 146 DUMMY_NODE_VECTOR3  DME,xx,DME;

EV_ U_E_Stoerung_EGS: 0 [0|4] "" 0 145 DUMMY_NODE_VECTOR3  EGS;

EV_ U_E_Steuergeraetetyp: 0 [0|1] "" 0 144 DUMMY_NODE_VECTOR3  EGS;

EV_ U_E_Status_ASC: 0 [0|1] "" 0 143 DUMMY_NODE_VECTOR3  ASC;

EV_ U_E_Shiftlock: 0 [0|3] "" 0 142 DUMMY_NODE_VECTOR3  DME;

EV_ U_E_Shaft_Speed: 1 [0|255] "" 0 141 DUMMY_NODE_VECTOR3  EGS;

EV_ U_E_Sensorverschmutzung: 0 [0|1] "" 0 140 DUMMY_NODE_VECTOR3  DME,INSTR;

EV_ U_E_Schaltung_aktiv: 0 [0|1] "" 0 139 DUMMY_NODE_VECTOR3  EGS;

EV_ U_E_Schalter_Kupplung: 0 [0|1] "" 0 138 DUMMY_NODE_VECTOR3  DME;

EV_ U_E_Schalter_Kickdown: 0 [0|1] "" 0 137 DUMMY_NODE_VECTOR3  DME;

EV_ U_E_Schaltaufforderung_ACC: 0 [0|1] "" 0 136 DUMMY_NODE_VECTOR3  DME,INSTR;

EV_ U_E_Schaltaufforderung: 0 [0|1] "" 0 135 DUMMY_NODE_VECTOR3  DME;

EV_ U_E_Radgeschwindigkeit_RV: 1 [0|512] "" 0 134 DUMMY_NODE_VECTOR0 Vector__XXX;

EV_ U_E_Radgeschwindigkeit_RH: 1 [0|512] "" 0 133 DUMMY_NODE_VECTOR0 Vector__XXX;

EV_ U_E_Radgeschwindigkeit_LV: 1 [0|512] "" 0 132 DUMMY_NODE_VECTOR0 Vector__XXX;

EV_ U_E_Radgeschwindigkeit_LH: 1 [0|512] "" 0 131 DUMMY_NODE_VECTOR3 Vector__XXX;

EV_ U_E_Programminfo: 0 [0|8] "" 0 130 DUMMY_NODE_VECTOR3  EGS;

EV_ U_E_Position_Waehlhebel: 0 [0|16] "" 0 129 DUMMY_NODE_VECTOR3  EGS;

EV_ U_E_P_Luft: 0 [600|1106] "hPa" 1013 128 DUMMY_NODE_VECTOR3  DME;

EV_ U_E_Objekterfassung: 0 [0|1] "" 0 127 DUMMY_NODE_VECTOR3  DME,INSTR;

EV_ U_E_OBD_Fehler: 0 [0|1] "" 0 126 DUMMY_NODE_VECTOR3  DME;

EV_ U_E_OBD_EGS: 0 [0|16] "" 0 125 DUMMY_NODE_VECTOR3  EGS;

EV_ U_E_Multiplex_Daten_ACC: 0 [0|250] "" 0 124 DUMMY_NODE_VECTOR0 Vector__XXX;

EV_ U_E_Multiplex_Code_ACC: 0 [0|15] "" 0 123 DUMMY_NODE_VECTOR0 Vector__XXX;

EV_ U_E_Motoroelverlust: 0 [0|1] "" 0 122 DUMMY_NODE_VECTOR3  DME;

EV_ U_E_Motoroelverbrauch: 0 [0|1] "" 0 121 DUMMY_NODE_VECTOR3  DME;

EV_ U_E_Motoroeltemperatur: 0 [-48|206] "Grad C" 0 120 DUMMY_NODE_VECTOR3  DME;

EV_ U_E_Motoroelsensor_defekt: 0 [0|1] "" 0 119 DUMMY_NODE_VECTOR3  DME;

EV_ U_E_Motor_Temp_Sta: 0 [0|1] "" 0 118 DUMMY_NODE_VECTOR3  DME,DME;

EV_ U_E_Momenteneingriff_MSR: 0 [0|255] "" 0 117 DUMMY_NODE_VECTOR3  ASC;

EV_ U_E_Momenteneingriff_EGS: 1 [0|99.609] "" 0 116 DUMMY_NODE_VECTOR3  EGS;

EV_ U_E_Momenteneingriff_ASC_Luftmas: 1 [0|100] "" 0 115 DUMMY_NODE_VECTOR3  ASC;

EV_ U_E_Momenteneingriff_ASC: 0 [0|255] "" 0 114 DUMMY_NODE_VECTOR0 Vector__XXX;

EV_ U_E_Momentenanforderung_ACC: 0 [0|1] "" 0 113 DUMMY_NODE_VECTOR3  ASC,DDE,DME;

EV_ U_E_Momenteingriff_ACC: 1 [-20|275] "" 0 112 DUMMY_NODE_VECTOR3  ACC;

EV_ U_E_Momentaufnahme_Getriebe: 1 [0|99.6094] "" 0 111 DUMMY_NODE_VECTOR3  EGS;

EV_ U_E_Moment_ASC: 0 [0|1] "" 0 110 DUMMY_NODE_VECTOR3  DDE;

EV_ U_E_Last: 1 [1|101] "" 101 109 DUMMY_NODE_VECTOR3  xx,xx;

EV_ U_E_Lampe_FGR_aktiv: 0 [0|1] "" 0 108 DUMMY_NODE_VECTOR3  DME;

EV_ U_E_Lamp_Boost_Control: 0 [0|1] "" 0 107 DUMMY_NODE_VECTOR3  DME;

EV_ U_E_Katheizung_2: 0 [0|1] "" 0 106 DUMMY_NODE_VECTOR3  DDE;

EV_ U_E_Katheizung_1: 0 [0|1] "" 0 105 DUMMY_NODE_VECTOR0 Vector__XXX;

EV_ U_E_Kat_Heizung_aktiv: 0 [0|1] "" 0 104 DUMMY_NODE_VECTOR3  DME;

EV_ U_E_Kat_Heizung: 0 [0|1] "" 0 103 DUMMY_NODE_VECTOR3  DME,DME;

EV_ U_E_Getriebestrangverstaerkung: 1 [0|127.875] "" 0 102 DUMMY_NODE_VECTOR3  EGS;

EV_ U_E_Getriebeschutz: 0 [0|1] "" 0 101 DUMMY_NODE_VECTOR3  EGS;

EV_ U_E_Getriebeoeluebertemperatur: 0 [0|1] "" 0 100 DUMMY_NODE_VECTOR3  EGS;

EV_ U_E_Getriebeoelkuehlung: 0 [0|1] "" 0 99 DUMMY_NODE_VECTOR3  EGS;

EV_ U_E_Geschw_ACC_Regelobjektes: 0 [0|250] "" 0 98 DUMMY_NODE_VECTOR3  INSTR;

EV_ U_E_Gemittelte_Geschwindigkeit: 1 [0|511.938] "" 0 97 DUMMY_NODE_VECTOR3  ASC;

EV_ U_E_FGR_aktiv: 0 [0|7] "" 0 96 DUMMY_NODE_VECTOR3  DME;

EV_ U_E_Fehler_V1_Signal: 0 [0|1] "" 0 95 DUMMY_NODE_VECTOR3  ASC;

EV_ U_E_Fehler_TL_mes: 0 [0|1] "" 0 94 DUMMY_NODE_VECTOR3  DDE;

EV_ U_E_Fehler_Drehzahl_Motor: 0 [0|1] "" 0 93 DUMMY_NODE_VECTOR0  DME;

EV_ U_E_Fehler_Bremsschaltersystem: 0 [0|1] "" 0 92 DUMMY_NODE_VECTOR3  DME;

EV_ U_E_Fahrerwunschgeschwindigkeit: 0 [0|1] "" 0 91 DUMMY_NODE_VECTOR3  DME;

EV_ U_E_Fahreruebernahme: 0 [0|1] "" 0 90 DUMMY_NODE_VECTOR3  DME;

EV_ U_E_ErrorFrame: 1 [1|101] "" 101 89 DUMMY_NODE_VECTOR3  xx,Last;

EV_ U_E_EKAT_Temperatur_2: 0 [-40|214] "" 20 88 DUMMY_NODE_VECTOR3  EKAT;

EV_ U_E_EKAT_Temperatur_1: 0 [-40|214] "" 20 87 DUMMY_NODE_VECTOR3  EKAT;

EV_ U_E_EKAT_Temp_Batterie: 0 [-40|215] "" 20 86 DUMMY_NODE_VECTOR3  EKAT;

EV_ U_E_EKAT_Konvbit: 0 [0|1] "" 0 85 DUMMY_NODE_VECTOR3  EKAT;

EV_ U_E_EKAT_Heizstrom_2: 0 [0|255] "" 0 84 DUMMY_NODE_VECTOR3  EKAT;

EV_ U_E_EKAT_Heizstrom_1: 0 [0|255] "" 0 83 DUMMY_NODE_VECTOR3  EKAT;

EV_ U_E_EKAT_Batteriespannung_2: 1 [0|25.5] "" 0 82 DUMMY_NODE_VECTOR3  EKAT;

EV_ U_E_EKAT_Batteriespannung_1: 1 [0|25.5] "" 0 81 DUMMY_NODE_VECTOR3  EKAT;

EV_ U_E_EKAT_Auswahl_Leistungssch: 0 [0|2] "" 0 80 DUMMY_NODE_VECTOR0 Vector__XXX;

EV_ U_E_Drehzahl: 1 [0|10000] "U/min" 0 79 DUMMY_NODE_VECTOR3  DME,DME;

EV_ U_E_DME4_Strombedarf_DME: 1 [0|45] "A" 0 78 DUMMY_NODE_VECTOR3  DME,DDE;

EV_ U_E_DME4_Signal_Tankdeckel: 0 [0|1] "" 0 77 DUMMY_NODE_VECTOR3  DME,DDE;

EV_ U_E_DME4_Generator_Vollast: 0 [0|1] "" 0 76 DUMMY_NODE_VECTOR3  DME,DDE;

EV_ U_E_DME4_Generator_Hochtempreg: 0 [0|1] "" 0 75 DUMMY_NODE_VECTOR3  DME,DDE;

EV_ U_E_DME4_Generator_defekt: 0 [0|1] "" 0 74 DUMMY_NODE_VECTOR3  DME,DDE;

EV_ U_E_DME2_Warmlauf: 0 [0|1] "" 0 73 DUMMY_NODE_VECTOR3  DDE;

EV_ U_E_DME2_Niveau_Leerlaufdrehz: 0 [0|1] "" 0 72 DUMMY_NODE_VECTOR3  DDE;

EV_ U_E_DME2_Motor_laeuft: 0 [0|1] "" 0 71 DUMMY_NODE_VECTOR3  DDE;

EV_ U_E_DIST_WARN: 0 [0|1000] "" 0 70 DUMMY_NODE_VECTOR3  DME;

EV_ U_E_DIST_VAL: 0 [0|1000] "" 0 69 DUMMY_NODE_VECTOR3  DME;

EV_ U_E_Diagnoseanzeige: 0 [0|1] "" 0 68 DUMMY_NODE_VECTOR3  DME;

EV_ U_E_Diagnose_DDE: 0 [0|1] "" 0 67 DUMMY_NODE_VECTOR3  DME,DME;

EV_ U_E_Check_Engine: 0 [0|1] "" 0 66 DUMMY_NODE_VECTOR3  DME,DME;

EV_ U_E_Bremsschalter: 0 [0|1] "" 0 65 DUMMY_NODE_VECTOR3  DME;

EV_ U_E_Bremslichtschalter: 0 [0|1] "" 0 64 DUMMY_NODE_VECTOR3  ASC;

EV_ U_E_Bremskraftverteilung_Lampe: 0 [0|1] "" 0 63 DUMMY_NODE_VECTOR3  ASC;

EV_ U_E_Bremseingriff_ACC: 1 [-20|275] "" 0 62 DUMMY_NODE_VECTOR3  ASC,DDE,DME,EGS;

EV_ U_E_Bremsassistent_Lampe: 0 [0|1] "" 0 61 DUMMY_NODE_VECTOR3  ASC;

EV_ U_E_Bremsanforderung_ACC: 0 [0|1] "" 0 60 DUMMY_NODE_VECTOR3  ASC,DDE,DME;

EV_ U_E_Bediensignal_FGR: 0 [0|7] "" 0 59 DUMMY_NODE_VECTOR3  DME;

EV_ U_E_Auswahl_ASC: 0 [0|1] "" 0 58 DUMMY_NODE_VECTOR1  ASC;

EV_ U_E_ASC4_Signal_rough_road: 0 [0|255] "" 0 57 DUMMY_NODE_VECTOR3  ASC;

EV_ U_E_ASC4_HDC_Status: 0 [0|7] "" 0 56 DUMMY_NODE_VECTOR3  ASC;

EV_ U_E_ASC4_HDC_fault: 0 [0|1] "" 0 55 DUMMY_NODE_VECTOR3  ASC;

EV_ U_E_ASC3_Schalter_HBA: 0 [0|1] "" 0 54 DUMMY_NODE_VECTOR3  ASC;

EV_ U_E_ASC3_Quittierung_ACC: 0 [0|1] "" 0 53 DUMMY_NODE_VECTOR3  ASC;

EV_ U_E_ASC3_FZG_Querbeschleunigung: 1 [-24.576|24.48] "m/(s*s)" 0 52 DUMMY_NODE_VECTOR3  ASC;

EV_ U_E_ASC3_FZG_Laengsbeschleu: 1 [-15.9688|15.9688] "m/(s*s)" 0 51 DUMMY_NODE_VECTOR3  ASC;

EV_ U_E_ASC3_Fahrerbremsung: 0 [0|0] "" 0 50 DUMMY_NODE_VECTOR3  ASC;

EV_ U_E_ASC3_DSC_Eingriff: 0 [0|1] "" 0 49 DUMMY_NODE_VECTOR3  ASC;

EV_ U_E_ASC3_Bremsassistent_Status: 0 [0|15] "" 0 48 DUMMY_NODE_VECTOR0 Vector__XXX;

EV_ U_E_ASC3_Bremsassistent_defekt: 0 [0|1] "" 0 47 DUMMY_NODE_VECTOR0  ASC;

EV_ U_E_ASC3_Bremsassistent_CODE: 0 [0|4] "" 0 46 DUMMY_NODE_VECTOR3  ASC;

EV_ U_E_ASC3_Auswahl_Info: 0 [0|0] "" 0 45 DUMMY_NODE_VECTOR0  ASC;

EV_ U_E_ASC2_Toleranzabgleich: 0 [0|1] "" 0 44 DUMMY_NODE_VECTOR3  ASC;

EV_ U_E_ASC2_COD: 0 [0|500] "" 0 43 DUMMY_NODE_VECTOR3  ASC;

EV_ U_E_ASC1_Rueckwaertsfahrt: 0 [0|1] "" 0 42 DUMMY_NODE_VECTOR3  ASC;

EV_ U_E_ASC1_Bremsflniveau: 0 [0|1] "" 0 41 DUMMY_NODE_VECTOR3  ASC;

EV_ U_E_ASC_Schaltbeeinflussung: 0 [0|1] "" 0 40 DUMMY_NODE_VECTOR3  ASC;

EV_ U_E_ASC_Lampe: 0 [0|1] "" 0 39 DUMMY_NODE_VECTOR3  ASC;

EV_ U_E_ASC_Bremsassistent_defekt: 0 [0|1] "" 0 38 DUMMY_NODE_VECTOR3  ASC;

EV_ U_E_ASC_Alive_Zaehler: 0 [0|16] "" 0 37 DUMMY_NODE_VECTOR3  ASC;

EV_ U_E_Anzahl_Batterien: 0 [0|1] "" 0 36 DUMMY_NODE_VECTOR3  DME;

EV_ U_E_Anforderung_MSR: 0 [0|1] "" 0 35 DUMMY_NODE_VECTOR3  ASC;

EV_ U_E_Anforderung_ASC: 0 [0|1] "" 0 34 DUMMY_NODE_VECTOR3  ASC;

EV_ U_E_Alive_Zaehler: 0 [0|15] "" 0 33 DUMMY_NODE_VECTOR3  ASC,DDE,DME;

EV_ U_E_ACC_Status: 0 [0|7] "" 0 32 DUMMY_NODE_VECTOR3  ASC,DME,EGS,INSTR;

EV_ U_E_ACC_Objekterfassung: 0 [0|1] "" 0 31 DUMMY_NODE_VECTOR3  DME,INSTR;

EV_ U_E_ACC_Defekt: 0 [0|1] "" 0 30 DUMMY_NODE_VECTOR3  ASC,DME,EGS,INSTR;

EV_ U_E_Abstandwunsch: 0 [0|3] "" 0 29 DUMMY_NODE_VECTOR3  DME,INSTR;

EV_ U_E_ABSASC_Eingriff: 0 [0|1] "" 0 28 DUMMY_NODE_VECTOR3  ASC;

EV_ U_E_ABS_defekt_Lampe: 0 [0|1] "" 0 27 DUMMY_NODE_VECTOR3  ASC;

EV_ U_A_Zielgang: 0 [0|8] "" 0 26 DUMMY_NODE_VECTOR3  DME;

EV_ U_A_Warmlauf_Anzeige: 0 [0|1] "" 0 25 DUMMY_NODE_VECTOR3  xx,INSTR;

EV_ U_A_Verbrauch: 0 [0|32767] "" 0 24 DUMMY_NODE_VECTOR3  xx,INSTR;

EV_ U_A_Tempomat: 0 [0|1] "" 0 23 DUMMY_NODE_VECTOR3  xx,INSTR;

EV_ U_A_T_MOT: 0 [-48|142] "" 0 22 DUMMY_NODE_VECTOR3  xx,INSTR;

EV_ U_A_System_Aktiv_Anzeige: 0 [0|0] "" 0 21 DUMMY_NODE_VECTOR3  xx,INSTR;

EV_ U_A_Programminfo: 0 [0|8] "" 0 20 DUMMY_NODE_VECTOR3  xx,INSTR;

EV_ U_A_Position_Waehlhebel: 0 [0|10] "" 0 19 DUMMY_NODE_VECTOR3  xx,INSTR;

EV_ U_A_Motor_Temperatur: 0 [0|1] "" 0 18 DUMMY_NODE_VECTOR3  xx,INSTR;

EV_ U_A_Mo: 0 [0|0] "" 0 17 DUMMY_NODE_VECTOR0 Vector__XXX;

EV_ U_A_Kat_Heizung: 0 [0|1] "" 0 16 DUMMY_NODE_VECTOR3  xx,INSTR;

EV_ U_A_Getriebe_Stoerung: 0 [0|1] "" 0 15 DUMMY_NODE_VECTOR3  xx,INSTR;

EV_ U_A_Fehler_Drehzahl_Motor: 0 [0|1] "" 0 14 DUMMY_NODE_VECTOR0 Vector__XXX;

EV_ U_A_elk_Kraftstoffpumpe: 0 [0|3] "" 0 13 DUMMY_NODE_VECTOR0 Vector__XXX;

EV_ U_A_EKP_5: 0 [0|15000] "" 0 12 DUMMY_NODE_VECTOR0 Vector__XXX;

EV_ U_A_Drehzahl: 0 [0|10000] "" 0 11 DUMMY_NODE_VECTOR3  xx,INSTR;

EV_ U_A_Diagnose_DDE: 0 [0|1] "" 0 10 DUMMY_NODE_VECTOR3  xx,INSTR;

EV_ U_A_Check_Engine: 0 [0|1] "" 0 9 DUMMY_NODE_VECTOR3  xx,INSTR;

EV_ U_A_ASC2_test: 0 [0|0] "" 0 8 DUMMY_NODE_VECTOR0 Vector__XXX;

EV_ U_A_ASC2_Radtoleranz_VR: 1 [-12.75|12.75] "" 0 7 DUMMY_NODE_VECTOR1  ASC;

EV_ U_A_ASC2_Radtoleranz_VL: 1 [-12.75|12.75] "" 0 6 DUMMY_NODE_VECTOR1  ASC;

EV_ U_A_ASC2_Radtoleranz_HR: 1 [-12.75|12.75] "" 0 5 DUMMY_NODE_VECTOR1  ASC;

EV_ U_A_ASC2_Radtoleranz_HL: 1 [-12.75|12.75] "" 0 4 DUMMY_NODE_VECTOR1  ASC;

EV_ U_A_ACC_Modus: 0 [0|1] "" 0 3 DUMMY_NODE_VECTOR3  xx,INSTR;

EV_ U_A_ACC_Defekt: 0 [0|1] "" 0 2 DUMMY_NODE_VECTOR3  xx,INSTR;

EV_ U_A_ACC_Aktiv: 0 [0|1] "" 0 1 DUMMY_NODE_VECTOR3  xx,INSTR;

CM_ BU_ TSG "Temperatur Steuergerät";
CM_ BU_ EKP "Elektronische Kraftstoff Pumpe";
CM_ BU_ DIP "wird von DME4 benötigt: Signal L_BCF";
CM_ BU_ BeCM "wird benötigt von TCU1: Signal TCU_CR";
CM_ BU_ AIR_SUS "wird benötigt von INSTR3: Signal S_REGIME";
CM_ BO_ 1583 "Temperatur Steuergerät
nur M-GmbH";
CM_ SG_ 1583 T_UMG "Umgebungstemperatur";
CM_ SG_ 1562 V_ODO_U "Units of trip distance";
CM_ SG_ 1562 V_COMP_U "Trip computer distance units";
CM_ SG_ 1562 V_TEMP_U "Trip computer units";
CM_ SG_ 1562 V_COMP_M "Trip computer mode";
CM_ SG_ 1562 V_TRIP1 "Trip distance 1";
CM_ SG_ 1562 V_SIA "Service interval counter";
CM_ SG_ 1562 V_ODO "ODO display value";
CM_ SG_ 1562 V_COMP "Numeric data for trip computer";
CM_ SG_ 1562 V_ID "Indicates multiplexed data";
CM_ SG_ 1562 V_LED "Tacho warning lamp";
CM_ SG_ 1562 V_WL "Warning light";
CM_ SG_ 1562 V_GPOS "Gear position display";
CM_ SG_ 1562 V_GEAR "Gear Mode";
CM_ SG_ 1560 T_EVAP_SIG "Evaporator temperature signe";
CM_ SG_ 1560 T_EVAP "Evaporator temperature";
CM_ SG_ 1560 S_GEAR "Manual transmission information";
CM_ SG_ 1560 V_FZG "Vehicle reference speed";
CM_ SG_ 1557 KEY_INFO "Key-Information";
CM_ SG_ 1557 V_ANZ "Anzeige Geschwindigkeit";
CM_ SG_ 1557 F_K_OBD "OBD Fehler im Kombi";
CM_ SG_ 1557 A_EKP_CRASH "Abschaltung EKP im Crash";
CM_ SG_ 1557 BLINKER "Fahrtrichtungsanzeige";
CM_ SG_ 1557 F_K_ACC "Fehler im Kombi für ACC System";
CM_ SG_ 1557 S_REGIME "Regime switch";
CM_ SG_ 1557 S_SUSP "Ride Height Status";
CM_ SG_ 1557 S_HBR "Handbrake Switch";
CM_ SG_ 1557 S_DOOR "Door Switch";
CM_ SG_ 1557 T_UMG_SIGN "Vorzeichen Umgebungstemperatur";
CM_ SG_ 1557 T_UMG "Umgebungstemperatur";
CM_ SG_ 1557 LB_NLL "Anforderung Leerlaufdrehzahlerhöhung";
CM_ SG_ 1557 N_EL "Drehtzahl / Stufe Elektrolüfter";
CM_ SG_ 1557 S_MH "Signal Motorhaubenkontakt";
CM_ SG_ 1557 S_TNS "Schalter Tag/Nacht-Beleuchtung";
CM_ SG_ 1557 S_ANH "Schalter Anhängerbetrieb";
CM_ SG_ 1557 S_HZL "Anforderung Heizleistung";
CM_ SG_ 1557 S_AC "Schalter Klimabereitschaft";
CM_ SG_ 1557 S_KO "Schalter Klimakompressor";
CM_ SG_ 1557 S_NTKW "Anforderung niedrige Kühlmitteltemp. bei Kennfeldkühlung";
CM_ SG_ 1557 LM_KK "Lastmoment Klimakompressor";
CM_ SG_ 1555 FST_LINKS "Füllstand linker Tank";
CM_ SG_ 1555 REL_ZEIT "Relative Minutenzähler";
CM_ SG_ 1555 S_FST "Schalter Tank-Füllstand (Reservekontankt)";
CM_ SG_ 1555 FST "Tank-Füllstand";
CM_ SG_ 1555 KM_ST "Kilometerstand";
CM_ SG_ 1552 SCALE_INFO "Einheit des Tacho Ziffernblatts";
CM_ SG_ 1552 FGSTNR_C1 "Fahrgestellnummer: Buchstabe 1";
CM_ SG_ 1552 FGSTNR_C2 "Fahrgestellnummer: Buchstabe 2";
CM_ SG_ 1552 FGSTNR "Fahrgestellnummer";
CM_ SG_ 1552 FGSTNR_P "Fahrgestellnummer: Prüfzahl";
CM_ SG_ 1505 GEE "Benzinenergieäquivalent";
CM_ SG_ 1505 FTL_GAS "Tankfüllstand in % für Anzeigekombi";
CM_ SG_ 1505 LV_BFS "Schaltsignal für Bifuel Betrieb";
CM_ SG_ 1505 LV_FRS_GAS "Logische Variable zur Schaltung der Reservelampe im Erdgasbetrieb";
CM_ SG_ 1505 LV_POW_RED "Logische Variable zur Schaltung der Anzeige \"Reduzierte Leistung\"";
CM_ SG_ 1503 EDCK_STA2 "Systemstatus EDCK Low-ULONG";
CM_ SG_ 1503 EDCK_STA1 "Systemstatus EDCK High-ULONG";
CM_ SG_ 1502 L_HIGH "High Suspension Warning";
CM_ SG_ 1502 SUSP_INFO "Air Suspension Message code";
CM_ SG_ 1502 L_ACCESS "Access Lamp";
CM_ SG_ 1502 L_WADE "Wade Lamp";
CM_ SG_ 1500 NIVEAU "Status Niveau";
CM_ SG_ 1500 KO_ST "Kompressoransteuerung";
CM_ SG_ 1500 QSV_OFFEN "Status Quersperrventile offen";
CM_ SG_ 1500 EHC_DEF "EHC Defektanzeige";
CM_ SG_ 1500 HOE_HR "Höhenstand hinten rechts";
CM_ SG_ 1500 HOE_HL "Höhenstand hinten links";
CM_ SG_ 1500 HOE_VR "Höhenstand vorne rechts";
CM_ SG_ 1500 HOE_VL "Höhenstand vorne links";
CM_ SG_ 1381 P_MAP_G "Manifold pressure";
CM_ SG_ 1381 SEC_P_CODE "Secondary Pressure Special Code";
CM_ SG_ 1381 SEC_P_RAT "Desired Secondary Pressure Duty Ratio";
CM_ SG_ 1381 CLUTCH_CODE "Clutch Special Codes";
CM_ SG_ 1381 CLUTCH_RAT "Desired Clutch Duty Ratio";
CM_ SG_ 1381 MOT_SPEED "Desired Motor Speed";
CM_ SG_ 1381 MOT_SCODE "Motor Special Codes";
CM_ SG_ 1381 MOT_POS "Desired Motor Position";
CM_ SG_ 1365 V_FZG_DME "Vehicle reference speed
(identical to V_FZG but transmitted from DME)";
CM_ SG_ 1349 L_P_OIL "Anzeige Motoröldruck";
CM_ SG_ 1349 S_DDS "Schalter Reifenpannen Warnsystem";
CM_ SG_ 1349 BEDARF_EKP "Bedarfsmenge Kraftstoff";
CM_ SG_ 1349 S_KL30H "Status Anlasser";
CM_ SG_ 1349 I_DMESYS "Strombedarf DME/DDE-System";
CM_ SG_ 1349 GEN_LAST "Generator Vollast";
CM_ SG_ 1349 GEN_HTAR "Generator Hochtemperaturabregelung";
CM_ SG_ 1349 GEN_DEF "Anzeige Generator defekt";
CM_ SG_ 1349 M_OEL_TEMP "Motoröltemperatur";
CM_ SG_ 1349 SCHALT "Schaltaufforderung";
CM_ SG_ 1349 TMOT_KALT "Anzeige kalter Motor";
CM_ SG_ 1349 TMOT_STA "Statusanzeige Übertemperatur";
CM_ SG_ 1349 MOL_SF "Info Motorölsensor defekt";
CM_ SG_ 1349 MOL_VL "Info Motorölverlust";
CM_ SG_ 1349 MOL_VB "Info Motorölverbrauch";
CM_ SG_ 1349 VERBRAUCH "Kraftstoffverbrauch";
CM_ SG_ 1349 BATT_ANZ "Anzahl der Batterien im Bordnetz";
CM_ SG_ 1349 S_TDL "Schalter Tankdeckel
switch filler cap";
CM_ SG_ 1349 L_BCF "Lamp Boost Control Failure";
CM_ SG_ 1349 L_DIAG "Diagnoseanzeige DDE/DME mit integrierter EML-Funktionalität";
CM_ SG_ 1349 L_FGR "Bereitschaftsanzeige MainSwitch";
CM_ SG_ 1349 S_SHL "Schnelles Hochladen";
CM_ SG_ 1349 L_MIL "Lampe \"check engine\" für OBD";
CM_ SG_ 1349 L_HEIZ "Vorglühlampe";
CM_ BO_ 1328 "Steuergerät Booster Function Control";
CM_ SG_ 1328 BFC_ALIVE "BFC Alive Signal";
CM_ SG_ 1328 BFC_STAT "BFC Status";
CM_ SG_ 1328 BFC_PVK "Vakuumkammerdruck";
CM_ SG_ 1328 BFC_PAK "Arbeitskammerdruck";
CM_ SG_ 1324 ACC_GONG "Gonganforderung ACC";
CM_ SG_ 1324 DIST_ANZ "Anzeige des eingestellten Abstandswunsches";
CM_ SG_ 1324 SHIFTREQ "Schaltaufforderung";
CM_ SG_ 1324 SEN_DTY "Anzeige Sensor verschmutzt";
CM_ SG_ 1324 TAKEOVER "Fahrerübernahmeaufforderung";
CM_ SG_ 1324 OBJVALID "ACC relevantes Objekt erfaßt";
CM_ SG_ 1324 VSET "Fahrer Wunschgeschwindigkeit";
CM_ SG_ 1324 BRE_ACC "Bremseneingriff für ACC-Funktion, bezogen auf BRE_NORM";
CM_ SG_ 1324 MD_IND_ACC "Momenteneingriff für ACC-Funktion, bezogen auf BRE_NORM";
CM_ SG_ 1324 VOBJECT "Daten für Multiplexsignal";
CM_ SG_ 1324 ACC_ALIVE "Alive Zähler";
CM_ SG_ 1324 ACC_MUL_CODE "Code für Multiplexsignal";
CM_ SG_ 1324 B_MD_B_BRE "Bedienung Momentenanforderung";
CM_ SG_ 1324 ACC_STAT "Status ACC";
CM_ SG_ 1324 ACC_DEF "ACC Defektanzeige";
CM_ SG_ 1324 ACC_VSA "Anforderung der Verhinderung der Schubabschaltung";
CM_ SG_ 1315 U_SBATT_LS1 "Batteriespannung Leistungsschalter 1";
CM_ SG_ 1315 U_SBATT_LS2 "Batteriespannung Leistungsschalter 2";
CM_ SG_ 1315 I_LS1 "Heizstrom Leistungsschalter 1";
CM_ SG_ 1315 I_LS2 "Heizstrom Leistungsschalter 2";
CM_ SG_ 1315 T_LS1 "Temperatur Leistungsschalter 1";
CM_ SG_ 1315 T_LS2 "Temperatur Leistungsschalter 2";
CM_ SG_ 1315 LS1_2 "Auswahlbit Leistungsschalter 1 oder 2";
CM_ SG_ 1315 T_BATT "EKAT Batterietemperatur";
CM_ SG_ 1315 KONV_BIT "Konfigurationsbit 1-/2-flutig";
CM_ SG_ 1315 KAT_STAT2 "Statusmeldung EKAT";
CM_ SG_ 1315 KAT_STAT1 "Statusmeldung EKAT";
CM_ SG_ 1315 KAT_STAT0 "Statusmeldung EKAT";
CM_ SG_ 1103 NUM_SWARE "Software number";
CM_ SG_ 1103 P_CON_SEC "Secondary pressure condition codes";
CM_ SG_ 1103 P_DUTY_SEC "Actual secondary pressure duty ratio";
CM_ SG_ 1103 STAT_L_F "PRNDM LED fault status";
CM_ SG_ 1103 CON_CLU_CODE "Clutch condition codes";
CM_ SG_ 1103 CLU_RAT_A "Actual clutch duty ratio";
CM_ SG_ 1103 STAT_L_D "PRNDM led drive status";
CM_ SG_ 1103 CON_MOT_CODE "Motor condition codes";
CM_ SG_ 1103 POS_MOT_A "Actual motor position";
CM_ SG_ 1103 S_STAT_H "Switch status high";
CM_ SG_ 1103 S_STAT_L "Switch status low";
CM_ SG_ 1097 VLS_GAS_2_PREV_DIAG "Spannungsrohwert 2nd downstream oxygen sensor - bank no 2";
CM_ SG_ 1097 VLS_GAS_1_PREV_DIAG "Spannungsrohwert 2nd downstream oxygen sensor - bank no 1";
CM_ SG_ 1097 MUX_GAS "Multiplex signal CNG";
CM_ SG_ 1097 SW_DET "Software Erkennung";
CM_ SG_ 1097 V_PGAS_H "Gasdruck high side";
CM_ SG_ 1097 V_PGAS_L "Gasdruck low side";
CM_ SG_ 1097 LV_GIG_2 "Rückmeldung digital reserve 2";
CM_ SG_ 1097 LV_DIG_1 "Rückmeldung digital reserve 1";
CM_ SG_ 1097 LV_SWI_PGAS "Rückmeldung pressure switch";
CM_ SG_ 1097 LV_CRASH "Rückmeldung Crash-Abschaltung";
CM_ SG_ 1097 LV_BFS "Rückmeldung bi fuel switch";
CM_ SG_ 1095 RAM_IN "RAM-Zellenübertragung input";
CM_ SG_ 1095 T_PEAK_IV_GAS_TI "Peak time for natural gas injection valves";
CM_ SG_ 1095 T_PEAK_EXPV "Peak time for the expansion valve";
CM_ SG_ 1095 LV_OUT_4 "Reserve";
CM_ SG_ 1095 LV_HWP "Schalter für Heizwasserpumpe";
CM_ SG_ 1095 LV_FUEL_ENA "Schalter für Benzinbetrieb";
CM_ SG_ 1095 LV_GAS_ENA "Schalter für Gasbetrieb";
CM_ SG_ 1095 LV_LS_GAS_2_DIAG "Diagnose 2nd downstream oxygen sensor for natural gas -bank no 2";
CM_ SG_ 1095 LV_LS_GAS_1_DIAG "Diagnose 2nd downstream oxygen sensor for natural gas -bank no 1";
CM_ SG_ 1095 LV_OUT_2 "Reserve";
CM_ SG_ 1095 LV_OUT_1 "Reserve";
CM_ SG_ 1095 LV_HEAT_PCD "Ansteuerung heater pressure control device";
CM_ SG_ 1095 LV_SOV_GAS_PCD "Ansteuerung shut off valve pressure control device";
CM_ SG_ 1095 LV_SOV_GAS_H_2 "Ansteuerung shut off valve bottle 2 high side";
CM_ SG_ 1095 LV_SOV_GAS_H_1 "Ansteuerung shut off valve bottle 1 high side";
CM_ SG_ 1095 LV_EXPV "Ansteuerung expansion valve";
CM_ SG_ 1095 LSHPWM_GAS_2 "Ansteuerung heating for 2nd downstream oxygen sensor for natural gas - bank no 2";
CM_ SG_ 1095 LSHPWM_GAS_1 "Ansteuerung heating for 2nd downstream oxygen sensor for natural gas - bank no 1";
CM_ SG_ 1093 TXU_GANG_ANZ "Display required Gear";
CM_ SG_ 1093 TXU_RANGE_ANZ "Display Transfer Case Rage";
CM_ SG_ 1093 TXU_COGS_ANZ "Display Transfer Case Cogs";
CM_ SG_ 1093 L_TXU "Warning light transfer case control unit";
CM_ SG_ 1093 TXU_SM "Status manuell Transmission";
CM_ SG_ 1093 OBD_STAT_TXU "OBD-Status Transfer Case Control Unit";
CM_ SG_ 1093 MC_IND_TXU "Torque override for TXU function";
CM_ SG_ 1093 TXU_STAT "TXU Status";
CM_ SG_ 1093 TXU_ERR "TXU Error Status";
CM_ SG_ 1093 TXU_SL_REQ "Shiftlock Request";
CM_ SG_ 1093 TXU_TR "Target Range Status";
CM_ SG_ 1093 TXU_CR "Current Range Status";
CM_ SG_ 1089 MD_IND_CRT_LM "Momenteneingriff des CRT-Getriebes bezogen auf das indizierte Motormoment / Luftmassensteuerung";
CM_ SG_ 1089 MD_IND_CRT_KOMPL "Bitweises Komplement zu MD_IND_CRT";
CM_ SG_ 1089 MD_IND_CRT "Momenteneingriff des CRT-Getriebes bezogen auf das indizierte 
Motormoment / gesamt (Luftmasse + Zündwinkel)
";
CM_ SG_ 1089 UEB_GETR_IST "ÜBERSETZUNGSVERHÄLTNIS_GETRIEBE_IST Momentan vorhandenes Übersetzungsverhältnis";
CM_ SG_ 1089 MD_TOGGLE "MD_TOGGLE Togglebit";
CM_ SG_ 1089 STATUS_GANG "Status eingelegter Gang";
CM_ SG_ 1089 LL_ERHOEHUNG "LL_ERHÖHUNG Anforderung Leerlaufdrehzahlerhöhung";
CM_ SG_ 1089 CRT_VSA "Verhinderung Schubabschalten";
CM_ SG_ 1087 MD_GETRIEBE "Momentaufnahme Getriebe";
CM_ SG_ 1087 STR_VERST "Getriebe Strang Verstärkung";
CM_ SG_ 1087 S_GOT "Schalter Getriebeöl Übertemperatur";
CM_ SG_ 1087 S_EGW "Schalter Getriebeölkühlung";
CM_ SG_ 1087 GS_TYP "Steuergerätetyp EGS/SMG";
CM_ SG_ 1087 L_GS "Störanzeige";
CM_ SG_ 1087 N_ABTR "Output shaft speed";
CM_ SG_ 1087 MD_IND_GS "Momenteneingriff der GS bezogen auf das indizierte Motormoment";
CM_ SG_ 1087 PRG_INF_ANZ "Programminformationsanzeige";
CM_ SG_ 1087 SMG_WHL_ANZ "SMG Wählhebelstellung";
CM_ SG_ 1087 OBD_STAT_GS "OBD-Status Getriebesteuerung";
CM_ SG_ 1087 GANG_WHL_ANZ "Positionswählhebelanzeige";
CM_ SG_ 1087 S_WK "Wandlerkupplung";
CM_ SG_ 1087 S_GTS "Schalter Getriebeschutz";
CM_ SG_ 1087 OBD_F "OBD-relevanter Fehler";
CM_ SG_ 1087 S_SCHALT "Schaltung aktiv";
CM_ SG_ 1087 GANG_INF "Zielgang";
CM_ SG_ 822 B_TW_FAULT "Torque intervention failure";
CM_ SG_ 822 TW_NORM "Maximum absolute torque at wheels";
CM_ SG_ 822 TW_IND_NE "Absolute actual torque at wheels";
CM_ SG_ 809 W_FPDK_MOD "Modifiziertes Fahrpedal";
CM_ SG_ 809 S_SHIFTLOCK "Anforderung Shiftlock";
CM_ SG_ 809 B_FGR "Status Fahrgeschwindigkeitsregler";
CM_ SG_ 809 S_KD "Schalter Kickdown";
CM_ SG_ 809 F_BS "Fehler Bremslichtschalter";
CM_ SG_ 809 S_BS "Bremslichtschalter";
CM_ SG_ 809 W_FPDK "Winkel Fahrpedal/Drosselklappe";
CM_ SG_ 809 W_VP_FGR "Winkel virtuelles FGR-Pedal";
CM_ SG_ 809 BED_FGR "Bediensignal FGR";
CM_ SG_ 809 S_WL "Schalter Warmlauf";
CM_ SG_ 809 Q_ACC_DME "Quittierung ACC";
CM_ SG_ 809 S_NIV_LL "Schalter Niveau Leerlaufdrehzahl";
CM_ SG_ 809 S_KUP "Schalter Kupplung";
CM_ SG_ 809 P_LUFT "Gemessener Luftdruck";
CM_ SG_ 809 T_MOT "Motortemperatur";
CM_ SG_ 809 MUL_COD "Kennzeichnung der Information MUL_INFO";
CM_ SG_ 809 MD_NORM "Normierungsfaktor für Momentenschnittstelle";
CM_ SG_ 809 OBD_STEUER "OBD Steuerfunktion";
CM_ SG_ 809 CAN_STAND "CAN Stand";
CM_ SG_ 790 MD_IND_LM "Indiziertes Motormoment nach Füllungseingriff";
CM_ SG_ 790 L_TP_SW "Throttle pedal fault switch";
CM_ SG_ 790 TP_SW "Throttle pedal switch";
CM_ SG_ 790 S_EZA "Anzeige Zylinderausfall";
CM_ SG_ 790 S_KATH2 "Schalter KAT-Heizung Bank links";
CM_ SG_ 790 S_KATH1 "Schalter KAT-Heizung Bank rechts";
CM_ SG_ 790 MD_REIB "Reibmoment";
CM_ SG_ 790 MD_IND "Indiziertes Motormoment";
CM_ SG_ 790 N_MOT "Motordrehzahl";
CM_ SG_ 790 MD_IND_NE "Indiziertes Motormoment nach Momenteneingriff";
CM_ SG_ 790 F_TL_MES "Fehler TL_MES-Signal";
CM_ SG_ 790 S_KOREL "Ansteuerung Klimakompressorrelais";
CM_ SG_ 790 STAT_MD_E "Status Momenteneingriff";
CM_ SG_ 790 S_ZAF "Anzeige Zylinderausfall";
CM_ SG_ 790 Q_ASC "Quittung ASC";
CM_ SG_ 790 F_N_MOT "Fehler N_MOT-Signal";
CM_ SG_ 790 S_KL15 "Status Klemme 15";
CM_ SG_ 504 TW_IND_MSR "Absolute torque at wheels decrease request from MSR";
CM_ SG_ 504 TW_IND_ASC "Absolute torque at wheels decrease request from ASC";
CM_ SG_ 504 RDR_HR "Rad-Drehrichtung hinten rechts";
CM_ SG_ 504 RDR_HL "Rad-Drehrichtung hinten links";
CM_ SG_ 504 RDR_VR "Rad-Drehrichtung vorne rechts";
CM_ SG_ 504 RDR_VL "Rad-Drehrichtung vorne links";
CM_ SG_ 504 P_BREAK "Signal Brake Pressure";
CM_ SG_ 504 B_OFFROAD "Signal Offroad";
CM_ SG_ 504 B_TW_ASC "ASC only torque decrease request active";
CM_ SG_ 504 B_TW_MSR "MSR only torque increase request active";
CM_ SG_ 504 L_HDC "Hill Descent Control Fault";
CM_ SG_ 504 S_HDC "Hill Descent Control";
CM_ SG_ 504 S_WHEEL_ACC "Signal Wheel Acceleration";
CM_ SG_ 501 LWS_BK_SIGN "LWS Bahnkrümmung";
CM_ SG_ 501 LWS_PSIPKT_SIGN "LWS Giergeschwindigkeit";
CM_ SG_ 501 LWS_AY_SIGN "LWS Querbeschleunigung";
CM_ SG_ 501 LWS_BK "LWS Bahnkrümmung";
CM_ SG_ 501 LWS_AY "LWS Querbeschleunigung";
CM_ SG_ 501 LWS_PSIPKT "LWS Giergeschwindigkeit";
CM_ SG_ 501 LWS_ANA "Analoge Sensorspannung";
CM_ SG_ 501 LWS_CNT "Telegrammzähler";
CM_ SG_ 501 LWS_STAT "Interner Status";
CM_ SG_ 501 LWS_ID "Lenkradwinkelsensor Identifier";
CM_ SG_ 501 LWS_LRWPKT_SIGN "Vorzeichen Lenkradwinkelgeschwindigkeit";
CM_ SG_ 501 LWS_LRWPKT "Lenkradwinkelgeschwindigkeit";
CM_ SG_ 501 LWS_LRW_SIGN "Vorzeichen des LWS Lenkradwinkels";
CM_ SG_ 501 LWS_LRW "LWS Lenkradwinkel";
CM_ SG_ 499 S_FZGSTD "Signal Fahrzeugstillstand";
CM_ SG_ 499 L_DDS "Lampe Reifenpanne Warnsystem";
CM_ SG_ 499 DSC_DEF "DSC Stabilisierung nicht möglich";
CM_ SG_ 499 AY_REF "Fahrzeug Querbeschleunigung";
CM_ SG_ 499 S_HBA "Schalter HBA aktiv";
CM_ SG_ 499 DSC_REG "DSC-Eingriff";
CM_ SG_ 499 AX_REF "Fahrzeug Längsbeschleunigung";
CM_ SG_ 499 BAS_STAT "Bremsassistent Statusanzeige";
CM_ SG_ 499 BAS_FBR "Fahrerbremsung";
CM_ SG_ 499 Q_ACC_BAS "Quittierung zum ACC System";
CM_ SG_ 499 BAS_DEF "Bremsassistent Defektanzeige";
CM_ SG_ 499 FDR_ID "Identifier für Lenkradwinkelsensor Initialisierung";
CM_ SG_ 499 FDR_PSIPKT "Giergeschwindigkeit absolut";
CM_ SG_ 499 FDR_PSIPKT_STATUS "Giergeschwindigkeit Status";
CM_ SG_ 499 FDR_COM "Auswahl der Information";
CM_ SG_ 496 VRD_RH_ASC "Radgeschwindigkeit rechts hinten";
CM_ SG_ 496 VRD_LH_ASC "Radgeschwindigkeit links hinten";
CM_ SG_ 496 VRD_RV_ASC "Radgeschwindigkeit rechts vorne";
CM_ SG_ 496 VRD_LV_ASC "Radgeschwindigkeit links vorne";
CM_ SG_ 339 S_BFL "Signal Bremsflüssigkeitsniveau";
CM_ SG_ 339 S_RWF "Signal Rückwärtsfahrt";
CM_ SG_ 339 L_BFC "Ausfall Boosterüberwachung";
CM_ SG_ 339 L_BKV "Ausfall Bremskraftverstärker";
CM_ SG_ 339 L_FLUID "Low brake fluid warning";
CM_ SG_ 339 S_ALR "Status Allradantrieb";
CM_ SG_ 339 MD_IND_ASC_LM "Momenteneingriff für ASC-Funktion über die Füllung (Luftmasse),
bezogen auf MD_NORM";
CM_ SG_ 339 W_VDK "Winkel Vordrosselklappe";
CM_ SG_ 339 MD_IND_MSR "Mementeneingriff für MSR-Funktion, bezogen auf MD_NORM";
CM_ SG_ 339 MD_IND_ASC "Momenteneingriff für ASC-Funktion, bezogen auf MD_NORM";
CM_ SG_ 339 V1 "Mittlere Vorderradgeschwindigkeit";
CM_ SG_ 339 F_V1 "Fehler V1-Signal";
CM_ SG_ 339 ASC_REG "ABS/ASC-Eingriff";
CM_ SG_ 339 L_ASC "ASC Lampe";
CM_ SG_ 339 L_ABS "ABS Defektanzeige";
CM_ SG_ 339 L_EBV "Lampe elektronische Bremskraftverteilung";
CM_ SG_ 339 L_BAS "Lampe Bremsassistent";
CM_ SG_ 339 S_BLS "Signal Bremslichtschalter";
CM_ SG_ 339 ASC_SBE "ASC Schaltbeinflussung";
CM_ SG_ 339 ASC_PAS "Status ASC passiv";
CM_ SG_ 339 B_MSR "Anfoderung MSR";
CM_ SG_ 339 B_ASC "Anforderung ASC";
CM_ EV_ U_S_TXU1_ZYKLUS_ZEIT "Zykluszeit der Botschaft";
CM_ EV_ U_S_TXU1_TOLERANZ_ZEIT "Toleranzzeit der Botschaft";
CM_ EV_ U_S_TXU1_SYNC_ZEIT "Falls die Botschaft zeitlich synchron zu einem anderen
Ereignis stattfindet, so enthält diese Variable diese
Synchronisationszeit";
CM_ EV_ U_S_TXU1_LATENZ_ZEIT "Latenzzeit der Botschaft";
CM_ EV_ U_S_TXU_STARTUP_ZEIT "Diese Umgebungsvariable legt das Aufstartverhalten
des Steuergerätes fest. Nach Ablauf
der in dieser Umgebungsvariablen angegebenen Zeit
beginnt das Steuergerät zu senden, falls nicht vorher 
bereits eine DME_DDE2-Botschaft empfangen wurde.
0 bedeutet Senden erst nach Empfang einer DME_DDE2-
  Botschaft und erfolgreichem Vergleich mit dem 
  eigenen CAN-Stand (U_S_???_CAN_STAND)
!= 0 bedeutet automatischer Sendebeginn nach 
  der angegebenen Zeit, wenn nicht vorher eine
  DME_DDE2-Botschaft empfangen wurde.";
CM_ EV_ U_S_TXU_SENDEN_KL_15 "Über diesen Wert wird das Sendeverhalten des Steuergerätes festgelegt
0 bedeutet Senden abhängig von Klemme 87
1 bedeutet Senden abhängig von Klemme 15";
CM_ EV_ U_S_TXU_CAN_STAND "CAN-Stand des Steuergerätes";
CM_ EV_ U_S_LWS1_ZYKLUS_ZEIT "Zykluszeit der Botschaft";
CM_ EV_ U_S_LWS1_TOLERANZ_ZEIT "Toleranzzeit der Botschaft";
CM_ EV_ U_S_LWS1_SYNC_ZEIT "Falls die Botschaft zeitlich synchron zu einem anderen
Ereignis stattfindet, so enthält diese Variable diese
Synchronisationszeit";
CM_ EV_ U_S_LWS1_LATENZ_ZEIT "Latenzzeit der Botschaft";
CM_ EV_ U_S_LWS_STARTUP_ZEIT "Diese Umgebungsvariable legt das Aufstartverhalten
des Steuergerätes fest. Nach Ablauf
der in dieser Umgebungsvariablen angegebenen Zeit
beginnt das Steuergerät zu senden, falls nicht vorher 
bereits eine DME_DDE2-Botschaft empfangen wurde.
0 bedeutet Senden erst nach Empfang einer DME_DDE2-
  Botschaft und erfolgreichem Vergleich mit dem 
  eigenen CAN-Stand (U_S_???_CAN_STAND)
!= 0 bedeutet automatischer Sendebeginn nach 
  der angegebenen Zeit, wenn nicht vorher eine
  DME_DDE2-Botschaft empfangen wurde.";
CM_ EV_ U_S_LWS_SENDEN_KL_15 "Über diesen Wert wird das Sendeverhalten des Steuergerätes festgelegt
0 bedeutet Senden abhängig von Klemme 87
1 bedeutet Senden abhängig von Klemme 15";
CM_ EV_ U_S_LWS_CAN_STAND "CAN-Stand des Steuergerätes";
CM_ EV_ U_S_KOMBI_STARTUP_ZEIT "Diese Umgebungsvariable legt das Aufstartverhalten
des Steuergerätes fest. Nach Ablauf
der in dieser Umgebungsvariablen angegebenen Zeit
beginnt das Steuergerät zu senden, falls nicht vorher 
bereits eine DME_DDE2-Botschaft empfangen wurde.
0 bedeutet Senden erst nach Empfang einer DME_DDE2-
  Botschaft und erfolgreichem Vergleich mit dem 
  eigenen CAN-Stand (U_S_???_CAN_STAND)
!= 0 bedeutet automatischer Sendebeginn nach 
  der angegebenen Zeit, wenn nicht vorher eine
  DME_DDE2-Botschaft empfangen wurde.";
CM_ EV_ U_S_KOMBI_SENDEN_KL_15 "Über diesen Wert wird das Sendeverhalten des Steuergerätes festgelegt
0 bedeutet Senden abhängig von Klemme 87
1 bedeutet Senden abhängig von Klemme 15";
CM_ EV_ U_S_KOMBI_CAN_STAND "CAN-Stand des Steuergerätes";
CM_ EV_ U_S_KL_87_HALTEZEIT "Haltezeit der Klemme 87 nach Unterschreiten der
Drehzahlschwelle nach Klemme 15 aus";
CM_ EV_ U_S_KL_87_DREHZAHLSCHWELLE "Drehzahlschwelle für Klemme 87 nach Ausschalten 
der Klemme 15";
CM_ EV_ U_S_KL_87 "Status der Klemme 87";
CM_ EV_ U_S_KL_15 "Status der Klemme 15";
CM_ EV_ U_S_INSTR4_ZYKLUS_ZEIT "Zykluszeit der Botschaft";
CM_ EV_ U_S_INSTR4_TOLERANZ_ZEIT "Toleranzzeit der Botschaft";
CM_ EV_ U_S_INSTR4_SYNC_ZEIT "Falls die Botschaft zeitlich synchron zu einem anderen
Ereignis stattfindet, so enthält diese Variable diese
Synchronisationszeit";
CM_ EV_ U_S_INSTR4_LATENZ_ZEIT "Latenzzeit der Botschaft";
CM_ EV_ U_S_INSTR3_ZYKLUS_ZEIT "Zykluszeit der Botschaft";
CM_ EV_ U_S_INSTR3_TOLERANZ_ZEIT "Toleranzzeit der Botschaft";
CM_ EV_ U_S_INSTR3_SYNC_ZEIT "Falls die Botschaft zeitlich synchron zu einem anderen
Ereignis stattfindet, so enthält diese Variable diese
Synchronisationszeit";
CM_ EV_ U_S_INSTR3_LATENZ_ZEIT "Latenzzeit der Botschaft";
CM_ EV_ U_S_INSTR2_ZYKLUS_ZEIT "Zykluszeit der Botschaft";
CM_ EV_ U_S_INSTR2_TOLERANZ_ZEIT "Toleranzzeit der Botschaft";
CM_ EV_ U_S_INSTR2_SYNC_ZEIT "Falls die Botschaft zeitlich synchron zu einem anderen
Ereignis stattfindet, so enthält diese Variable diese
Synchronisationszeit";
CM_ EV_ U_S_INSTR2_LATENZ_ZEIT "Latenzzeit der Botschaft";
CM_ EV_ U_S_INSTR1_ZYKLUS_ZEIT "Zykluszeit der Botschaft";
CM_ EV_ U_S_INSTR1_TOLERANZ_ZEIT "Toleranzzeit der Botschaft";
CM_ EV_ U_S_INSTR1_SYNC_ZEIT "Falls die Botschaft zeitlich synchron zu einem anderen
Ereignis stattfindet, so enthält diese Variable diese
Synchronisationszeit";
CM_ EV_ U_S_INSTR1_LATENZ_ZEIT "Latenzzeit der Botschaft";
CM_ EV_ U_S_EKAT1_ZYKLUS_ZEIT "Zykluszeit der Botschaft";
CM_ EV_ U_S_EKAT1_TOLERANZ_ZEIT "Toleranzzeit der Botschaft";
CM_ EV_ U_S_EKAT1_SYNC_ZEIT "Falls die Botschaft zeitlich synchron zu einem anderen
Ereignis stattfindet, so enthält diese Variable diese
Synchronisationszeit";
CM_ EV_ U_S_EKAT1_LATENZ_ZEIT "Latenzzeit der Botschaft";
CM_ EV_ U_S_EKAT_STARTUP_ZEIT "Diese Umgebungsvariable legt das Aufstartverhalten
des Steuergerätes fest. Nach Ablauf
der in dieser Umgebungsvariablen angegebenen Zeit
beginnt das Steuergerät zu senden, falls nicht vorher 
bereits eine DME_DDE2-Botschaft empfangen wurde.
0 bedeutet Senden erst nach Empfang einer DME_DDE2-
  Botschaft und erfolgreichem Vergleich mit dem 
  eigenen CAN-Stand (U_S_???_CAN_STAND)
!= 0 bedeutet automatischer Sendebeginn nach 
  der angegebenen Zeit, wenn nicht vorher eine
  DME_DDE2-Botschaft empfangen wurde.";
CM_ EV_ U_S_EKAT_SENDEN_KL_15 "Über diesen Wert wird das Sendeverhalten des Steuergerätes festgelegt
0 bedeutet Senden abhängig von Klemme 87
1 bedeutet Senden abhängig von Klemme 15";
CM_ EV_ U_S_EKAT_CAN_STAND "CAN-Stand des Steuergerätes";
CM_ EV_ U_S_EHC1_ZYKLUS_ZEIT "Zykluszeit der Botschaft";
CM_ EV_ U_S_EHC1_TOLERANZ_ZEIT "Toleranzzeit der Botschaft";
CM_ EV_ U_S_EHC1_SYNC_ZEIT "Falls die Botschaft zeitlich synchron zu einem anderen
Ereignis stattfindet, so enthält diese Variable diese
Synchronisationszeit";
CM_ EV_ U_S_EHC1_LATENZ_ZEIT "Latenzzeit der Botschaft";
CM_ EV_ U_S_EHC_STARTUP_ZEIT "Diese Umgebungsvariable legt das Aufstartverhalten
des Steuergerätes fest. Nach Ablauf
der in dieser Umgebungsvariablen angegebenen Zeit
beginnt das Steuergerät zu senden, falls nicht vorher 
bereits eine DME_DDE2-Botschaft empfangen wurde.
0 bedeutet Senden erst nach Empfang einer DME_DDE2-
  Botschaft und erfolgreichem Vergleich mit dem 
  eigenen CAN-Stand (U_S_???_CAN_STAND)
!= 0 bedeutet automatischer Sendebeginn nach 
  der angegebenen Zeit, wenn nicht vorher eine
  DME_DDE2-Botschaft empfangen wurde.";
CM_ EV_ U_S_EHC_SENDEN_KL_15 "Über diesen Wert wird das Sendeverhalten des Steuergerätes festgelegt
0 bedeutet Senden abhängig von Klemme 87
1 bedeutet Senden abhängig von Klemme 15";
CM_ EV_ U_S_EHC_CAN_STAND "CAN-Stand des Steuergerätes";
CM_ EV_ U_S_EGS1_ZYKLUS_ZEIT "Zykluszeit der Botschaft";
CM_ EV_ U_S_EGS1_TOLERANZ_ZEIT "Toleranzzeit der Botschaft";
CM_ EV_ U_S_EGS1_SYNC_ZEIT "Falls die Botschaft zeitlich synchron zu einem anderen
Ereignis stattfindet, so enthält diese Variable diese
Synchronisationszeit";
CM_ EV_ U_S_EGS1_LATENZ_ZEIT "Latenzzeit der Botschaft";
CM_ EV_ U_S_EGS_STARTUP_ZEIT "Diese Umgebungsvariable legt das Aufstartverhalten
des Steuergerätes fest. Nach Ablauf
der in dieser Umgebungsvariablen angegebenen Zeit
beginnt das Steuergerät zu senden, falls nicht vorher 
bereits eine DME_DDE2-Botschaft empfangen wurde.
0 bedeutet Senden erst nach Empfang einer DME_DDE2-
  Botschaft und erfolgreichem Vergleich mit dem 
  eigenen CAN-Stand (U_S_???_CAN_STAND)
!= 0 bedeutet automatischer Sendebeginn nach 
  der angegebenen Zeit, wenn nicht vorher eine
  DME_DDE2-Botschaft empfangen wurde.";
CM_ EV_ U_S_EGS_SENDEN_KL_15 "Über diesen Wert wird das Sendeverhalten des Steuergerätes festgelegt
0 bedeutet Senden abhängig von Klemme 87
1 bedeutet Senden abhängig von Klemme 15";
CM_ EV_ U_S_EGS_CAN_STAND "CAN-Stand des Steuergerätes";
CM_ EV_ U_S_EDCK1_ZYKLUS_ZEIT "Zykluszeit der Botschaft";
CM_ EV_ U_S_EDCK1_TOLERANZ_ZEIT "Toleranzzeit der Botschaft";
CM_ EV_ U_S_EDCK1_SYNC_ZEIT "Falls die Botschaft zeitlich synchron zu einem anderen
Ereignis stattfindet, so enthält diese Variable diese
Synchronisationszeit";
CM_ EV_ U_S_EDCK1_LATENZ_ZEIT "Latenzzeit der Botschaft";
CM_ EV_ U_S_EDCK_STARTUP_ZEIT "Diese Umgebungsvariable legt das Aufstartverhalten
des Steuergerätes fest. Nach Ablauf
der in dieser Umgebungsvariablen angegebenen Zeit
beginnt das Steuergerät zu senden, falls nicht vorher 
bereits eine DME_DDE2-Botschaft empfangen wurde.
0 bedeutet Senden erst nach Empfang einer DME_DDE2-
  Botschaft und erfolgreichem Vergleich mit dem 
  eigenen CAN-Stand (U_S_???_CAN_STAND)
!= 0 bedeutet automatischer Sendebeginn nach 
  der angegebenen Zeit, wenn nicht vorher eine
  DME_DDE2-Botschaft empfangen wurde.";
CM_ EV_ U_S_EDCK_SENDEN_KL_15 "Über diesen Wert wird das Sendeverhalten des Steuergerätes festgelegt
0 bedeutet Senden abhängig von Klemme 87
1 bedeutet Senden abhängig von Klemme 15";
CM_ EV_ U_S_EDCK_CAN_STAND "CAN-Stand des Steuergerätes";
CM_ EV_ U_S_DSC3_ZYKLUS_ZEIT "Zykluszeit der Botschaft";
CM_ EV_ U_S_DSC3_TOLERANZ_ZEIT "Toleranzzeit der Botschaft";
CM_ EV_ U_S_DSC3_SYNC_ZEIT "Falls die Botschaft zeitlich synchron zu einem anderen
Ereignis stattfindet, so enthält diese Variable diese
Synchronisationszeit";
CM_ EV_ U_S_DSC3_LATENZ_ZEIT "Latenzzeit der Botschaft";
CM_ EV_ U_S_DSC2_ZYKLUS_ZEIT "Zykluszeit der Botschaft";
CM_ EV_ U_S_DSC2_TOLERANZ_ZEIT "Toleranzzeit der Botschaft";
CM_ EV_ U_S_DSC2_SYNC_ZEIT "Falls die Botschaft zeitlich synchron zu einem anderen
Ereignis stattfindet, so enthält diese Variable diese
Synchronisationszeit";
CM_ EV_ U_S_DSC2_LATENZ_ZEIT "Latenzzeit der Botschaft";
CM_ EV_ U_S_DSC1_ZYKLUS_ZEIT "Zykluszeit der Botschaft";
CM_ EV_ U_S_DSC1_TOLERANZ_ZEIT "Toleranzzeit der Botschaft";
CM_ EV_ U_S_DSC1_SYNC_ZEIT "Falls die Botschaft zeitlich synchron zu einem anderen
Ereignis stattfindet, so enthält diese Variable diese
Synchronisationszeit";
CM_ EV_ U_S_DSC1_LATENZ_ZEIT "Latenzzeit der Botschaft";
CM_ EV_ U_S_DME4_ZYKLUS_ZEIT "Zykluszeit der Botschaft";
CM_ EV_ U_S_DME4_TOLERANZ_ZEIT "Toleranzzeit der Botschaft";
CM_ EV_ U_S_DME4_SYNC_ZEIT "Falls die Botschaft zeitlich synchron zu einem anderen
Ereignis stattfindet, so enthält diese Variable diese
Synchronisationszeit";
CM_ EV_ U_S_DME4_LATENZ_ZEIT "Latenzzeit der Botschaft";
CM_ EV_ U_S_DME2_ZYKLUS_ZEIT "Zykluszeit der Botschaft";
CM_ EV_ U_S_DME2_TOLERANZ_ZEIT "Toleranzzeit der Botschaft";
CM_ EV_ U_S_DME2_SYNC_ZEIT "Falls die Botschaft zeitlich synchron zu einem anderen
Ereignis stattfindet, so enthält diese Variable diese
Synchronisationszeit";
CM_ EV_ U_S_DME2_LATENZ_ZEIT "Latenzzeit der Botschaft";
CM_ EV_ U_S_DME1_ZYKLUS_ZEIT "Zykluszeit der Botschaft";
CM_ EV_ U_S_DME1_TOLERANZ_ZEIT "Toleranzzeit der Botschaft";
CM_ EV_ U_S_DME1_SYNC_ZEIT "Falls die Botschaft zeitlich synchron zu einem anderen
Ereignis stattfindet, so enthält diese Variable diese
Synchronisationszeit";
CM_ EV_ U_S_DME1_LATENZ_ZEIT "Latenzzeit der Botschaft";
CM_ EV_ U_S_DME_STARTUP_ZEIT "Diese Umgebungsvariable legt das Aufstartverhalten
des Steuergerätes fest. Nach Ablauf
der in dieser Umgebungsvariablen angegebenen Zeit
beginnt das Steuergerät zu senden, falls nicht vorher 
bereits eine DME_DDE2-Botschaft empfangen wurde.
0 bedeutet Senden erst nach Empfang einer DME_DDE2-
  Botschaft und erfolgreichem Vergleich mit dem 
  eigenen CAN-Stand (U_S_???_CAN_STAND)
!= 0 bedeutet automatischer Sendebeginn nach 
  der angegebenen Zeit, wenn nicht vorher eine
  DME_DDE2-Botschaft empfangen wurde.";
CM_ EV_ U_S_DME_SENDEN_KL_15 "Über diesen Wert wird das Sendeverhalten des Steuergerätes festgelegt
0 bedeutet Senden abhängig von Klemme 87
1 bedeutet Senden abhängig von Klemme 15";
CM_ EV_ U_S_DME_CAN_STAND "CAN-Stand des Steuergerätes";
CM_ EV_ U_S_DDE4_ZYKLUS_ZEIT "Zykluszeit der Botschaft";
CM_ EV_ U_S_DDE4_TOLERANZ_ZEIT "Toleranzzeit der Botschaft";
CM_ EV_ U_S_DDE4_SYNC_ZEIT "Falls die Botschaft zeitlich synchron zu einem anderen
Ereignis stattfindet, so enthält diese Variable diese
Synchronisationszeit";
CM_ EV_ U_S_DDE4_LATENZ_ZEIT "Latenzzeit der Botschaft";
CM_ EV_ U_S_DDE2_ZYKLUS_ZEIT "Zykluszeit der Botschaft";
CM_ EV_ U_S_DDE2_TOLERANZ_ZEIT "Toleranzzeit der Botschaft";
CM_ EV_ U_S_DDE2_SYNC_ZEIT "Falls die Botschaft zeitlich synchron zu einem anderen
Ereignis stattfindet, so enthält diese Variable diese
Synchronisationszeit";
CM_ EV_ U_S_DDE2_LATENZ_ZEIT "Latenzzeit der Botschaft";
CM_ EV_ U_S_DDE1_ZYKLUS_ZEIT "Zykluszeit der Botschaft";
CM_ EV_ U_S_DDE1_TOLERANZ_ZEIT "Toleranzzeit der Botschaft";
CM_ EV_ U_S_DDE1_SYNC_ZEIT "Falls die Botschaft zeitlich synchron zu einem anderen
Ereignis stattfindet, so enthält diese Variable diese
Synchronisationszeit";
CM_ EV_ U_S_DDE1_LATENZ_ZEIT "Latenzzeit der Botschaft";
CM_ EV_ U_S_DDE_STARTUP_ZEIT "Diese Umgebungsvariable legt das Aufstartverhalten
des Steuergerätes fest. Nach Ablauf
der in dieser Umgebungsvariablen angegebenen Zeit
beginnt das Steuergerät zu senden, falls nicht vorher 
bereits eine DME_DDE2-Botschaft empfangen wurde.
0 bedeutet Senden erst nach Empfang einer DME_DDE2-
  Botschaft und erfolgreichem Vergleich mit dem 
  eigenen CAN-Stand (U_S_???_CAN_STAND)
!= 0 bedeutet automatischer Sendebeginn nach 
  der angegebenen Zeit, wenn nicht vorher eine
  DME_DDE2-Botschaft empfangen wurde.Diese Umgebungsvariable legt das Aufstartverhalten
des Steuergerätes fest. Nach Ablauf
der in dieser Umgebungsvariablen angegebenen Zeit
beginnt das Steuergerät zu senden, falls nicht vorher 
bereits eine DME_DDE2-Botschaft empfangen wurde.
0 bedeutet Senden erst nach Empfang einer DME_DDE2-
  Botschaft und erfolgreichem Vergleich mit dem 
  eigenen CAN-Stand (U_S_???_CAN_STAND)
!= 0 bedeutet automatischer Sendebeginn nach 
  der angegebenen Zeit, wenn nicht vorher eine
  DME_DDE2-Botschaft empfangen wurde.";
CM_ EV_ U_S_DDE_SENDEN_KL_15 "Über diesen Wert wird das Sendeverhalten des Steuergerätes festgelegt
0 bedeutet Senden abhängig von Klemme 87
1 bedeutet Senden abhängig von Klemme 15";
CM_ EV_ U_S_DDE_CAN_STAND "CAN-Stand des Steuergerätes";
CM_ EV_ U_S_ASP_STARTUP_ZEIT "Diese Umgebungsvariable legt das Aufstartverhalten
des Steuergerätes fest. Nach Ablauf
der in dieser Umgebungsvariablen angegebenen Zeit
beginnt das Steuergerät zu senden, falls nicht vorher 
bereits eine DME_DDE2-Botschaft empfangen wurde.
0 bedeutet Senden erst nach Empfang einer DME_DDE2-
  Botschaft und erfolgreichem Vergleich mit dem 
  eigenen CAN-Stand (U_S_???_CAN_STAND)
!= 0 bedeutet automatischer Sendebeginn nach 
  der angegebenen Zeit, wenn nicht vorher eine
  DME_DDE2-Botschaft empfangen wurde.";
CM_ EV_ U_S_ASP_SENDEN_KL_15 "Über diesen Wert wird das Sendeverhalten des Steuergerätes festgelegt
0 bedeutet Senden abhängig von Klemme 87
1 bedeutet Senden abhängig von Klemme 15";
CM_ EV_ U_S_ASP_CAN_STAND "CAN-Stand des Steuergerätes";
CM_ EV_ U_S_ASG_STARTUP_ZEIT "Diese Umgebungsvariable legt das Aufstartverhalten
des Steuergerätes fest. Nach Ablauf
der in dieser Umgebungsvariablen angegebenen Zeit
beginnt das Steuergerät zu senden, falls nicht vorher 
bereits eine DME_DDE2-Botschaft empfangen wurde.
0 bedeutet Senden erst nach Empfang einer DME_DDE2-
  Botschaft und erfolgreichem Vergleich mit dem 
  eigenen CAN-Stand (U_S_???_CAN_STAND)
!= 0 bedeutet automatischer Sendebeginn nach 
  der angegebenen Zeit, wenn nicht vorher eine
  DME_DDE2-Botschaft empfangen wurde.";
CM_ EV_ U_S_ASG_SENDEN_KL_15 "Über diesen Wert wird das Sendeverhalten des Steuergerätes festgelegt
0 bedeutet Senden abhängig von Klemme 87
1 bedeutet Senden abhängig von Klemme 15";
CM_ EV_ U_S_ASG_CAN_STAND "CAN-Stand des Steuergerätes";
CM_ EV_ U_S_ASC4_ZYKLUS_ZEIT "Zykluszeit der Botschaft";
CM_ EV_ U_S_ASC3_ZYKLUS_ZEIT "Zykluszeit der Botschaft";
CM_ EV_ U_S_ASC3_TOLERANZ_ZEIT "Toleranzzeit der Botschaft";
CM_ EV_ U_S_ASC3_SYNC_ZEIT "Falls die Botschaft zeitlich synchron zu einem anderen
Ereignis stattfindet, so enthält diese Variable diese
Synchronisationszeit";
CM_ EV_ U_S_ASC3_LATENZ_ZEIT "Latenzzeit der Botschaft";
CM_ EV_ U_S_ASC2_ZYKLUS_ZEIT "Zykluszeit der Botschaft";
CM_ EV_ U_S_ASC2_TOLERANZ_ZEIT "Toleranzzeit der Botschaft";
CM_ EV_ U_S_ASC2_SYNC_ZEIT "Falls die Botschaft zeitlich synchron zu einem anderen
Ereignis stattfindet, so enthält diese Variable diese
Synchronisationszeit";
CM_ EV_ U_S_ASC2_LATENZ_ZEIT "Latenzzeit der Botschaft";
CM_ EV_ U_S_ASC1_ZYKLUS_ZEIT "Zykluszeit der Botschaft";
CM_ EV_ U_S_ASC1_TOLERANZ_ZEIT "Toleranzzeit der Botschaft";
CM_ EV_ U_S_ASC1_SYNC_ZEIT "Falls die Botschaft zeitlich synchron zu einem anderen
Ereignis stattfindet, so enthält diese Variable diese
Synchronisationszeit";
CM_ EV_ U_S_ASC1_LATENZ_ZEIT "Latenzzeit der Botschaft";
CM_ EV_ U_S_ASC_STARTUP_ZEIT "Diese Umgebungsvariable legt das Aufstartverhalten
des Steuergerätes fest. Nach Ablauf
der in dieser Umgebungsvariablen angegebenen Zeit
beginnt das Steuergerät zu senden, falls nicht vorher 
bereits eine DME_DDE2-Botschaft empfangen wurde.
0 bedeutet Senden erst nach Empfang einer DME_DDE2-
  Botschaft und erfolgreichem Vergleich mit dem 
  eigenen CAN-Stand (U_S_???_CAN_STAND)
!= 0 bedeutet automatischer Sendebeginn nach 
  der angegebenen Zeit, wenn nicht vorher eine
  DME_DDE2-Botschaft empfangen wurde.";
CM_ EV_ U_S_ASC_SENDEN_KL_15 "Über diesen Wert wird das Sendeverhalten des Steuergerätes festgelegt
0 bedeutet Senden abhängig von Klemme 87
1 bedeutet Senden abhängig von Klemme 15";
CM_ EV_ U_S_ASC_CAN_STAND "CAN-Stand des Steuergerätes";
CM_ EV_ U_S_ACC3_TOLERANZ_ZEIT "Toleranzzeit der Botschaft";
CM_ EV_ U_S_ACC1_ZYKLUS_ZEIT "Zykluszeit der Botschaft";
CM_ EV_ U_S_ACC1_TOLERANZ_ZEIT "Toleranzzeit der Botschaft";
CM_ EV_ U_S_ACC1_SYNC_ZEIT "Falls die Botschaft zeitlich synchron zu einem anderen
Ereignis stattfindet, so enthält diese Variable diese
Synchronisationszeit";
CM_ EV_ U_S_ACC1_LATENZ_ZEIT "Latenzzeit der Botschaft";
CM_ EV_ U_S_ACC_STARTUP_ZEIT "Diese Umgebungsvariable legt das Aufstartverhalten
des Steuergerätes fest. Nach Ablauf
der in dieser Umgebungsvariablen angegebenen Zeit
beginnt das Steuergerät zu senden, falls nicht vorher 
bereits eine DME_DDE2-Botschaft empfangen wurde.
0 bedeutet Senden erst nach Empfang einer DME_DDE2-
  Botschaft und erfolgreichem Vergleich mit dem 
  eigenen CAN-Stand (U_S_???_CAN_STAND)
!= 0 bedeutet automatischer Sendebeginn nach 
  der angegebenen Zeit, wenn nicht vorher eine
  DME_DDE2-Botschaft empfangen wurde.";
CM_ EV_ U_S_ACC_SENDEN_KL_15 "Über diesen Wert wird das Sendeverhalten des Steuergerätes festgelegt
0 bedeutet Senden abhängig von Klemme 87
1 bedeutet Senden abhängig von Klemme 15";
CM_ EV_ U_S_ACC_CAN_STAND "CAN-Stand des Steuergerätes";
CM_ EV_ U_H_Momenteingriff_ACC "Hilfsvariable für Eingabe von MD_IND_ACC (Momenteneingriff_ACC)
";
CM_ EV_ U_E_ASC3_Quittierung_ACC "siehe im Lastenheft unter ASC3 
Q_ACC_BAS
";
CM_ EV_ U_E_ASC3_Fahrerbremsung "siehe im Lastenheft unter ASC3 
BAS_FBR
";
CM_ EV_ U_E_ASC3_Bremsassistent_Status "siehe im Lastenheft unter ASC3 
BAS_STAT
";
VAL_ 1583 Vorzeichen 1 "Minus" 0 "Plus" ;
VAL_ 1562 V_ODO_U 1 "Miles" 0 "Km" ;
VAL_ 1562 V_COMP_U 1 "Miles" 0 "Km" ;
VAL_ 1562 V_TEMP_U 1 "F" 0 "C" ;
VAL_ 1562 V_COMP_M 1 "Average_display" 0 "Trip_display" ;
VAL_ 1562 V_SIA 2 "Service" 1 "Oil" 0 "Inspection" ;
VAL_ 1562 V_ID 1 "Trip_Computer_LCD_data" 0 "Odo_trip_LCD_data" ;
VAL_ 1562 V_LED 3 "LED1_2_3_on" 2 "LED1_2_on" 1 "LED1_on" 0 "All_off" ;
VAL_ 1562 V_GEAR 4 "Manual_transmission" 3 "Economy" 2 "Manual" 1 "Sport" 0 "Neutral" ;
VAL_ 1557 KEY_INFO 7 "FB4_FB_NR_liegt_vor" 6 "FB4_FB_NR_liegt_nicht_vor" 5 "FB3_FB_NR_liegt_vor" 4 "FB3_FB_NR_liegt_nicht_vor" 3 "FB2_FB_NR_liegt_vor" 2 "FB2_FB_NR_liegt_nicht_vor" 1 "FB1_FB_NR_liegt_vor" 0 "FB1_FB_NR_liegt_nicht_vor" ;
VAL_ 1557 A_EKP_CRASH 3 "Abschaltung_der_EKP_bei_vorher01" 2 "Fehler_keine_Abschaltung_der_EKP" 1 "Arming_keine_Abschaltung_der_EKP" 0 "keine_Abschaltung_der_EKP" ;
VAL_ 1557 BLINKER 3 "Warnblinker_ein" 2 "Blinker_rechts_ein" 1 "Blinker_links_ein" 0 "keine_Anzeige" ;
VAL_ 1557 F_K_ACC 1 "ACC_relevanter_Fehlerstatus" 0 "kein_ACC_relevanter_Fehlerstatus" ;
VAL_ 1557 S_REGIME 7 "Regimes_error" 4 "Manual" 3 "Tow" 2 "Economy" 1 "Sport" 0 "Normal" ;
VAL_ 1557 S_SUSP 3 "Error" 2 "Access" 1 "Wade" 0 "Default" ;
VAL_ 1557 S_HBR 1 "Handbrake_on" 0 "Handbrake_off" ;
VAL_ 1557 S_DOOR 1 "doors_open" 0 "doors_closed" ;
VAL_ 1557 T_UMG_SIGN 1 "negativer_Wert" 0 "positiver_Wert" ;
VAL_ 1557 LB_NLL 1 "Anforderung_erhoehte_Leerlaufdre" 0 "keine_Anforderung" ;
VAL_ 1557 S_MH 1 "Motorhaube_geoeffnet" 0 "Motorhaube_geschlossen" ;
VAL_ 1557 S_TNS 1 "" 0 "Tagbeleuchtung" ;
VAL_ 1557 S_ANH 1 "Anhaengerbetrieb" 0 "kein_Anhaengerbetrieb" ;
VAL_ 1557 S_HZL 1 "Anforderung_erhoehte_Heizleistun" 0 "Keine_Anforderung" ;
VAL_ 1557 S_AC 1 "Klimabereitschaft_ein" 0 "Klimabereitschaft_aus" ;
VAL_ 1557 S_KO 1 "Klimakompressor_zuschalten" 0 "Klimakompressor_ausschalten" ;
VAL_ 1557 S_NTKW 1 "Anforderung_niedrige_Kuehlmittel" 0 "Keine_Anforderung" ;
VAL_ 1555 S_FST 1 "Tankreserve_ein" 0 "Tankreserve_aus" ;
VAL_ 1505 LV_BFS 1 "Ansteuerung_ein" 0 "Ansteuerung_aus" ;
VAL_ 1505 LV_FRS_GAS 1 "Ansteuerung_ein" 0 "Ansteuerung_aus" ;
VAL_ 1505 LV_POW_RED 1 "Ansteuerung_ein" 0 "Ansteuerung_aus" ;
VAL_ 1500 NIVEAU 128 "Auf_Regelung" 64 "Ab_Regelung" 16 "Offroad" 8 "Standard" 4 "Motorway" 2 "Einstieg" ;
VAL_ 1500 KO_ST 1 "Kompressor_angesteuert" 0 "Kompressor_nicht_angesteuert" ;
VAL_ 1500 QSV_OFFEN 1 "Quersperrventil_offen" 0 "Quersperrventil_geschlossen" ;
VAL_ 1500 EHC_DEF 1 "EHC_defekt" 0 "EHC_i_O" ;
VAL_ 1381 MOT_SPEED 4 "_250" 3 "_167" 2 "_125" 1 "_50" 0 "Default_Motor_Speed" ;
VAL_ 1349 L_P_OIL 1 "Anzeigelampe_eingeschaltet" 0 "Anzeigelampe_ausgeschaltet" ;
VAL_ 1349 S_DDS 1 "Taster_betaetigt" 0 "Taster_nicht_betaetigt" ;
VAL_ 1349 S_KL30H 1 "Anlasser_ein" 0 "Anlasser_aus" ;
VAL_ 1349 GEN_LAST 1 "Generator_bei_max_Leistung" 0 "Generator_hat_Leistungsreserven" ;
VAL_ 1349 GEN_HTAR 1 "Generator_im_Hochtemperaturabreg" 0 "Generator_im_Normalbetrieb" ;
VAL_ 1349 GEN_DEF 1 "Generatorkontrollampe_ein" 0 "Generatorkontrollampe_aus" ;
VAL_ 1349 SCHALT 1 "Anzeige_der_Schaltaufforderung" 0 "keine_Anzeige" ;
VAL_ 1349 TMOT_KALT 7 "Fehler" 4 "Vier_Segmente_ein" 3 "Drei_Segmente_ein" 2 "Zwei_Segmente_ein" 1 "Ein_Segment_ein" 0 "Anzeigensegment_ausgeschaltet" ;
VAL_ 1349 TMOT_STA 1 "Anzeigelampe_eingeschaltet" 0 "Anzeigelampe_ausgeschaltet" ;
VAL_ 1349 MOL_SF 1 "Motoroelsensor_defekt" 0 "Motoroelsensor_i_O" ;
VAL_ 1349 MOL_VL 1 "Motoroelverlust" 0 "kein_Motoroelverlust" ;
VAL_ 1349 MOL_VB 1 "Motoroelverbrauch_nicht_i_O" 0 "Motoroelverbrauch_i_O" ;
VAL_ 1349 BATT_ANZ 1 "Bordnetz_mit_zwei_Batterien" 0 "Bordnetz_mit_einer_Batterie" ;
VAL_ 1349 S_TDL 1 "Tankdeckel_geoeffnet" 0 "Tankdeckel_geschlossen" ;
VAL_ 1349 L_BCF 1 "Lamp_illuminated" 0 "Lamp_off" ;
VAL_ 1349 L_DIAG 1 "Fehler_vorhanden" 0 "kein_Fehler" ;
VAL_ 1349 L_FGR 1 "FGR_ein" 0 "FGR_aus" ;
VAL_ 1349 S_SHL 1 "Starterbatterie_nicht_i_O" 0 "Starterbatterie_i_O" ;
VAL_ 1349 L_MIL 1 "Check_Engine_Lampe_ein" 0 "Check_Engine_Lampe_aus" ;
VAL_ 1349 L_HEIZ 1 "E_KAT_Heizung_ein_Vorgluehen" 0 "E_KAT_Heizung_aus_kein_Vorgluehe" ;
VAL_ 1324 ACC_GONG 3 "Fehler" 2 "Intermittierender_Gong_ACC" 1 "Einzel_Gong_ACC" 0 "keine_Anforderung" ;
VAL_ 1324 DIST_ANZ 3 "weit" 2 "mittel" 1 "nah" 0 "keine_Abstandsanzeige" ;
VAL_ 1324 SHIFTREQ 1 "Aufforderung_zu_schalten" 0 "keine_Aufforderung" ;
VAL_ 1324 SEN_DTY 1 "Sensor_verschmutzt" 0 "Sensor_sauber" ;
VAL_ 1324 TAKEOVER 1 "Fahreruebernahmeaufforderung" 0 "keine_Anforderung" ;
VAL_ 1324 OBJVALID 1 "relevantes_Objekt_erfasst" 0 "kein_relevantes_Objekt_erfasst" ;
VAL_ 1324 ACC_MUL_CODE 6 "DSET2LOW" 5 "DIST_VAL" 4 "DIST_WARN" 3 "VISI_VAL" 2 "VISI_WARN" 0 "VOBJECT" ;
VAL_ 1324 B_MD_B_BRE 3 "Fehler" 2 "Bremsanforderung" 1 "Momentenanforderung" 0 "keine_Anforderung" ;
VAL_ 1324 ACC_STAT 3 "Regelung_erhoehte_Dynamik" 2 "Regelung_Standard" 1 "aktiv_stand_by_mode" 0 "passiv" ;
VAL_ 1324 ACC_DEF 1 "System_mit_Fehler" 0 "System_ohne_Fehler" ;
VAL_ 1324 ACC_VSA 1 "Schubabschalten_verhindern" 0 "keine_Anforderung" ;
VAL_ 1097 LV_GIG_2 1 "digital_reserve_1_on" 0 "digital_reserve_1_off" ;
VAL_ 1097 LV_DIG_1 1 "digital_reserve_1_on" 0 "digital_reserve_1_off" ;
VAL_ 1097 LV_SWI_PGAS 1 "pressure_switch_on" 0 "pressure_switch_off" ;
VAL_ 1097 LV_CRASH 1 "Crash_Abschaltung" 0 "keine_Crash_Abschaltung" ;
VAL_ 1097 LV_BFS 1 "bi_fue_switch_ein" 0 "bi_fue_switch_aus" ;
VAL_ 1095 LV_OUT_4 1 "Ansteuerung_ein" 0 "Ansteuerung_aus" ;
VAL_ 1095 LV_HWP 1 "Ansteuerung_ein" 0 "Ansteuerung_aus" ;
VAL_ 1095 LV_FUEL_ENA 1 "Ansteuerung_ein" 0 "Ansteuerung_aus" ;
VAL_ 1095 LV_GAS_ENA 1 "Ansteuerung_ein" 0 "Ansteuerung_aus" ;
VAL_ 1095 LV_LS_GAS_2_DIAG 1 "Fehler" 0 "kein_Fehler" ;
VAL_ 1095 LV_LS_GAS_1_DIAG 1 "Fehler" 0 "kein_Fehler" ;
VAL_ 1095 LV_OUT_2 1 "Ansteuerung_ein" 0 "Ansteuerung_aus" ;
VAL_ 1095 LV_OUT_1 1 "Ansteuerung_ein" 0 "Ansteuerung_aus" ;
VAL_ 1095 LV_HEAT_PCD 1 "Ansteuerung_ein" 0 "Ansteuerung_aus" ;
VAL_ 1095 LV_SOV_GAS_PCD 1 "Ansteuerung_ein" 0 "Ansteuerung_aus" ;
VAL_ 1095 LV_SOV_GAS_H_2 1 "Ansteuerung_ein" 0 "Ansteuerung_aus" ;
VAL_ 1095 LV_SOV_GAS_H_1 1 "Ansteuerung_ein" 0 "Ansteuerung_aus" ;
VAL_ 1095 LV_PEAK_IV_GAS_TI 1 "Ansteuerung_ein" 0 "Ansteuerung_aus" ;
VAL_ 1095 LV_EXPV 1 "Ansteuerung_ein" 0 "Ansteuerung_aus" ;
VAL_ 1095 LSHPWM_GAS_2 1 "Ansteuerung_ein" 0 "Ansteuerung_aus" ;
VAL_ 1095 LSHPWM_GAS_1 1 "Ansteuerung_ein" 0 "Ansteuerung_aus" ;
VAL_ 1089 UEB_GETR_IST 255 "Fehler" ;
VAL_ 1089 MD_TOGGLE 3 "Fehler" 1 "Toggle_Bit_ist_gesetzt" 0 "Toggle_Bit_ist_nicht_gesetzt" ;
VAL_ 1089 STATUS_GANG 3 "Fehler" 2 "Gang_ist_eingelegt" 1 "Gangeinlegen_laeuft" 0 "Kein_Gang_eingelegt" ;
VAL_ 1089 LL_ERHOEHUNG 3 "Anforderung_LL_Erh_Stufe3" 2 "Anforderung_LL_Erh_Stufe2" 1 "Anforderung_LL_Erh_Stufe1" 0 "Keine_Anforderung" ;
VAL_ 1089 CRT_VSA 1 "Schubabschalten_verhindern" 0 "Keine_Anforderung" ;
VAL_ 1087 S_GOT 1 "Anforderung_zusaetzlicher_Kuehlu" 0 "keine_Anforderung" ;
VAL_ 1087 S_EGW 1 "Thermostat_bestromt" 0 "Thermostat_ohne_Bestromung" ;
VAL_ 1087 GS_TYP 1 "Steuergeraet_SMG" 0 "Steuergeraet_EGS" ;
VAL_ 1087 L_GS 1 "Getriebenotprogramm" 0 "kein_Fehler" ;
VAL_ 1087 PRG_INF_ANZ 7 "Stern_nicht_definiert" 6 "Leerzeichensechs_Balken" 5 "Anzeige_dunkel_fuenf_Balken" 4 "A_vier_Balken" 3 "W_drei_Balken" 2 "S_zwei_Balken" 1 "M_ein_Balken" 0 "E_kein_Balken" ;
VAL_ 1087 SMG_WHL_ANZ 3 "Rueckwaertsgang" 2 "Automat" 1 "Sequenziell" 0 "Neutral" ;
VAL_ 1087 GANG_WHL_ANZ 10 "sechs" 9 "fuenf" 7 "R" 6 "N" 5 "A" 4 "vier" 3 "drei" 2 "zwei" 1 "eins" 0 "Anzeige_dunkel" ;
VAL_ 1087 S_WK 3 "unbekannte_Stellung" 2 "Kupplung_geschlossen" 1 "Kupplung_geregelt" 0 "ausgekuppelt" ;
VAL_ 1087 S_GTS 1 "Erweiterter_Motoreingriff" 0 "Motoreingriff_nur_ueber_Zuendwin" ;
VAL_ 1087 OBD_F 1 "OBD_Fehler_vorhanden" 0 "kein_Fehler_vorhanden" ;
VAL_ 1087 S_SCHALT 1 "Schaltung_laeuft" 0 "keine_Schaltung" ;
VAL_ 1087 GANG_INF 7 "Rueckwaertsgang" 6 "sechster_Gang" 5 "fuenfter_Gang" 4 "vierter_Gang" 3 "dritter_Gang" 2 "zweiter_Gang" 1 "erster_Gang" 0 "N_oderP_kein_Kraftschluss" ;
VAL_ 809 S_SHIFTLOCK 3 "Anforderung_shiftlock_aktiv" 2 "Fehler_keine_Anforderung" 1 "Fehler_keine_Anforderung" 0 "keine_Anforderung" ;
VAL_ 809 B_FGR 7 "Fgr_aktiv_Verzoegern" 6 "FGR_ACC_Abschaltung" 5 "FGR_aktiv_Setzen_Beschleunigen" 4 "ACC_Regelung_Erhoete_Dynamik" 3 "FGR_aktiv_Wiederaufnahme" 2 "ACC_Regelung_Standard" 1 "FGR_aktiv_Konstantfahrt" 0 "FGR_passiv" ;
VAL_ 809 S_KD 1 "KD_aktiv" 0 "KD_nicht_aktiv" ;
VAL_ 809 F_BS 1 "Fehler_im_Bremsschaltersystem" 0 "Bremsschaltersystem_i_O" ;
VAL_ 809 S_BS 1 "Bremse_betaetigt" 0 "Bremse_nicht_betaetigt" ;
VAL_ 809 BED_FGR 7 "Fehler_liegt_vor" 3 "Wiederaufnahme" 4 "Abschalten" 2 "Verzgern" 1 "Setzen_Beschleunigen" 0 "keine_Bedienung" ;
VAL_ 809 S_ML 1 "Motor_laeuft" 0 "Motor_laeuft_nicht" ;
VAL_ 809 S_WL 1 "Motor_betriebswarm" 0 "Motor_im_Warmlauf_Katheizen_akti" ;
VAL_ 809 Q_ACC_DME 1 "Quittierung_ACC_i_O" 0 "Plaus_fehler_Aktivitaetserror" ;
VAL_ 809 S_NIV_LL 1 "LL_unterhalb_Schwelle" 0 "LL_oberhalb_Schwelle" ;
VAL_ 809 S_KUP 1 "Kupplung_betaetigt" 0 "Kupplung_nicht_betaetigt" ;
VAL_ 790 L_TP_SW 1 "Accelerator_pedal_fault" 0 "No_accelerator_pedal_fault" ;
VAL_ 790 TP_SW 1 "Accelerator_pedal_pressed" 0 "Accelerator_pedal_not_pressed" ;
VAL_ 790 S_EZA 1 "DME_im_EZA_Modus" 0 "DME_im_Normalbetrieb" ;
VAL_ 790 S_KATH2 1 "KAT_Heizung_Bank_2_ein" 0 "KAT_Heizung_Bank_2_aus" ;
VAL_ 790 S_KATH1 1 "KAT_Heizung_Bank_1_ein" 0 "KAT_Heizung_Bank_1_aus" ;
VAL_ 790 F_TL_MES 1 "Fehlerhaftes_TL_MES_Signal" 0 "kein_Fehler" ;
VAL_ 790 S_KOREL 1 "Klimakompressorrelais_ein" 0 "Klimakompressorrelais_aus" ;
VAL_ 790 STAT_MD_E 3 "DME_DDE_interner_Fehler" 2 "Stellgliedanschlag_Systemfehler" 1 "max_Zuendwinkel_erreicht" 0 "Eingriffswunsch_wird_ausgefuehrt" ;
VAL_ 790 S_ZAF 1 "Min_ein_Zylinder_ausgefallen" 0 "Kein_Zylinderausfall_erkannt" ;
VAL_ 790 Q_ASC 1 "kein_Plausibilitaetsfehler" 0 "Plausibilitaetsfehler" ;
VAL_ 790 F_N_MOT 1 "Drehzahlgeber_defekt" 0 "kein_Fehler" ;
VAL_ 790 S_KL15 1 "Kl_15_ein" 0 "Kl_15_aus_Selbsthaltephase" ;
VAL_ 504 RDR_HR 3 "Fehler" 2 "Rueckwaertsfahrt_erkannt" 1 "Vorwaertsfahrt_erkannt" 0 "Info_ist_ungueltig" ;
VAL_ 504 RDR_HL 3 "Fehler" 2 "Rueckwaertsfahrt_erkannt" 1 "Vorwaertsfahrt_erkannt" 0 "Info_ist_ungueltig" ;
VAL_ 504 RDR_VR 3 "Fehler" 2 "Rueckwaertsfahrt_erkannt" 1 "Vorwaertsfahrt_erkannt" 0 "Info_ist_ungueltig" ;
VAL_ 504 RDR_VL 3 "Fehler" 2 "Rueckwaertsfahrt_erkannt" 1 "Vorwaertsfahrt_erkannt" 0 "Info_ist_ungueltig" ;
VAL_ 504 B_OFFROAD 1 "Offroad_detected" 0 "Normal_road" ;
VAL_ 504 B_TW_ASC 1 "active" 0 "passive" ;
VAL_ 504 B_TW_MSR 1 "active" 0 "passive" ;
VAL_ 504 L_HDC 1 "HDC_fault" 0 "No_HDC_fault" ;
VAL_ 504 S_HDC 7 "HDC_error" 6 "HDC_enabled_lamp_is_flashing" 5 "HDC_enable_but_not_active" 4 "HDC_inaktiv_temporarily" 3 "HDC_disable_due_to_exessive_spee" 2 "HDC_disable_not_in_low_range" 1 "HDC_disable_not_in_correct_gear" 0 "HDC_off" ;
VAL_ 501 LWS_BK_SIGN 1 "negativ" 0 "positiv" ;
VAL_ 501 LWS_LRWPKT_SIGN 1 "negativ" 0 "positiv" ;
VAL_ 501 LWS_LRW_SIGN 1 "negativ" 0 "positiv" ;
VAL_ 499 S_FZGSTD 1 "Fahrzeugstillstand_erkannt" 0 "kein_Fahrzeugstillstand_erkannt" ;
VAL_ 499 L_DDS 3 "rote_Lampe_leuchtet_mit_Signal" 2 "rote_Lampe_leuchtet_kein_Signal" 1 "gelbe_Lampe_leuchtet_kein_Signal" 0 "Lampe_aus" ;
VAL_ 499 DSC_DEF 1 "Fehler_im_DSC_System" 0 "DSC_i_O" ;
VAL_ 499 BAS_CODE 3 "BAS_HYST2" 2 "BAS_HYST1" 1 "BRE_OFFSET" 0 "BRE_NORM" ;
VAL_ 499 S_HBA 1 "HBA_aktiv" 0 "HBA_inaktiv" ;
VAL_ 499 DSC_REG 1 "Eingriff_aktiv" 0 "kein_Eingriff" ;
VAL_ 499 BAS_STAT 10 "Vollbremshilfe_Bremsdruck_vorhan" 9 "ACC_Verzoegerungsreg_Bremsd_vorh" 8 "passiv_Bremsdruck_vorhanden" 2 "Vollbremshilfe_kein_Bremsdruck" 1 "ACC_Verzoegerungsreg_kein_Bremsd" 0 "passiv_kein_Bremsdruck" ;
VAL_ 499 BAS_FBR 3 "Fehler_Fahrerbremserkennung" 2 "Bremsung_groesser_Stellwert" 1 "Bremsung_kleiner_Stellwert" 0 "keine_Fahrerbremsung" ;
VAL_ 499 Q_ACC_BAS 1 "Quittierung_ACC_i_O" 0 "keine_Quittierung" ;
VAL_ 499 BAS_DEF 1 "Fehler_vorhanden" 0 "kein_Fehler" ;
VAL_ 499 FDR_PSIPKT_STATUS 1 "FDR_PSIPKT_fehlerhaft" 0 "FDR_PSIPKT_fehlerfrei" ;
VAL_ 339 S_BFL 1 "Bremsfluessigkeitsstand_ausreich" 0 "Bremsfluessigkeitsstand_niedrig" ;
VAL_ 339 S_RWF 1 "Rueckwaertsfahrt_erkannt" 0 "Vor_Rueckwaertsfahrt_nicht_erkan" ;
VAL_ 339 L_BFC 1 "Boosterueberwachung_ausgefallen" 0 "Boosterueberwachung_i_O" ;
VAL_ 339 L_BKV 1 "Bremskraftverstaerker_ausgefalle" 0 "Bremskraftverstaerker_i_O" ;
VAL_ 339 L_FLUID 1 "Brake_fluid_warnig_lamp_on" 0 "Brake_fluid_warnig_lamp_off" ;
VAL_ 339 S_ALR 1 "Allradantrieb" 0 "Heck_oder_Frontantrieb" ;
VAL_ 339 F_V1 1 "Fehler_an_min_2_Raddrehzahlgeber" 0 "min_ein_Geber_i_O" ;
VAL_ 339 ASC_REG 1 "Eingriff_aktiv" 0 "kein_Eingriff" ;
VAL_ 339 L_ASC 1 "ASV_Lampe_ein" 0 "ASC_Lampe_aus" ;
VAL_ 339 L_ABS 1 "ABS_Lampe_ein" 0 "ABS_Lampe_aus" ;
VAL_ 339 L_EBV 1 "EBV_Lampe_ein" 0 "EBV_Lampe_aus" ;
VAL_ 339 L_BAS 1 "Lampe_ein" 0 "Lampe_aus" ;
VAL_ 339 S_BLS 1 "Bremse_betaetigt" 0 "Bremse_nicht_betaetigt" ;
VAL_ 339 ASC_SBE 1 "aktiv" 0 "passiv" ;
VAL_ 339 ASC_PAS 1 "ASC_passiv" 0 "ASC_aktiv" ;
VAL_ U_E_FGR_aktiv 0 "passiv" 1 "aktiv_Konstantfahrt" 2 "ACC_Standard" 3 "aktiv_Wiederaufnahme" 4 "ACC_Erhoehte_Dynamik" 5 "aktiv_beschleunigen" 6 "ACC_Abschaltung" 7 "aktiv_verzoegern" ;
VAL_ U_E_Bediensignal_FGR 0 "keine_Bedienung" 1 "Setzen_Beschleunigen" 2 "Setzen_Verzgern" 3 "Wiederaufnahme" 4 "Abschalten" 5 "nicht_belegt" 6 "nicht_belegt" 7 "Fehler" ;
FILTER 0 CAT_ 0 BU_ EKAT ;
